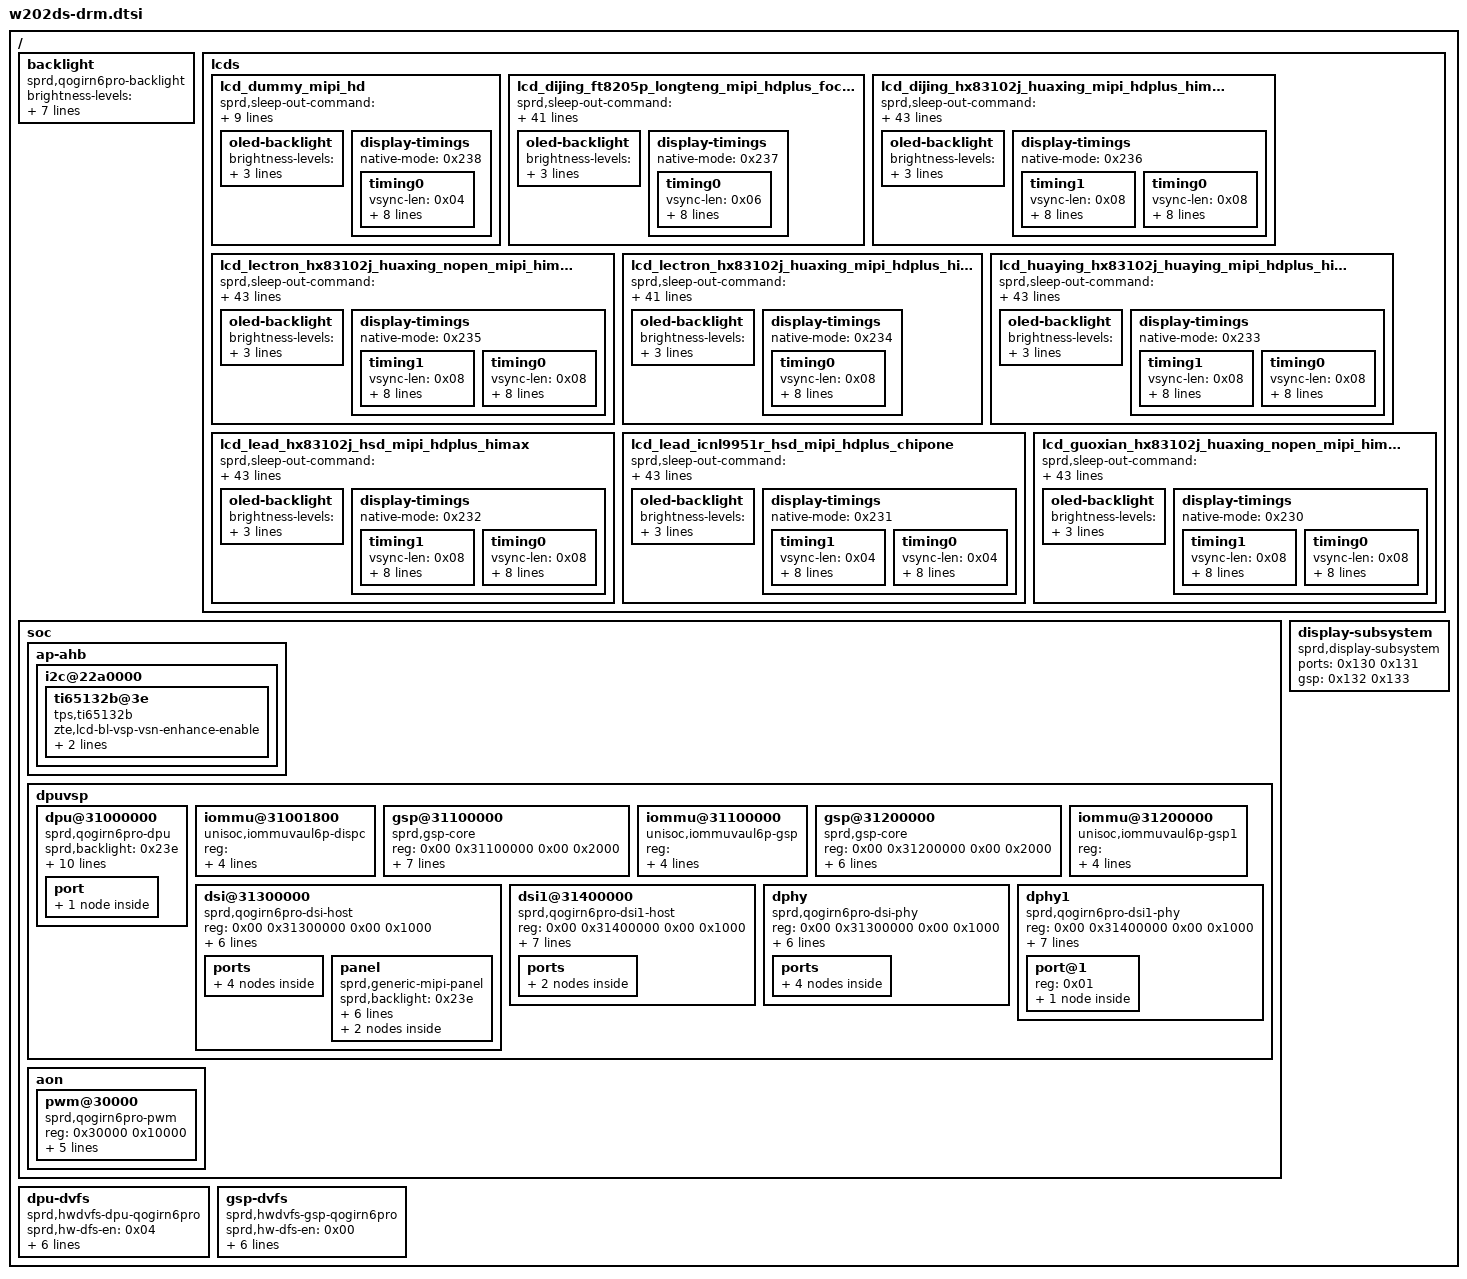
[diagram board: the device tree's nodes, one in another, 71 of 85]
// W202DS Server hardware layout; split from the validated imported tree.
/ {
	backlight {
		phandle = <0x23e>;
		brightness-levels = <0x00 0x0b 0x0b 0x0c 0x10 0x14 0x18 0x1c 0x20 0x24 0x28 0x2c 0x30 0x34 0x38 0x3c 0x40 0x44 0x48 0x4c 0x50 0x54 0x58 0x5c 0x60 0x64 0x68 0x6c 0x70 0x74 0x78 0x7c 0x80 0x84 0x88 0x8c 0x90 0x94 0x98 0x9c 0xa0 0xa4 0xa8 0xac 0xb0 0xb4 0xb8 0xbc 0xc0 0xc4 0xc8 0xcc 0xd0 0xd4 0xd8 0xdc 0xe0 0xe4 0xe8 0xec 0xf0 0xf4 0xf8 0xfc 0x100 0x104 0x108 0x10c 0x110 0x114 0x118 0x11c 0x120 0x124 0x128 0x12c 0x130 0x134 0x138 0x13c 0x140 0x144 0x148 0x14c 0x150 0x155 0x159 0x15d 0x161 0x165 0x169 0x16d 0x171 0x175 0x179 0x17d 0x181 0x185 0x189 0x18d 0x191 0x195 0x199 0x19d 0x1a1 0x1a5 0x1a9 0x1ad 0x1b1 0x1b5 0x1b9 0x1bd 0x1c1 0x1c5 0x1c9 0x1cd 0x1d1 0x1d5 0x1d9 0x1dd 0x1e1 0x1e5 0x1e9 0x1ed 0x1f1 0x1f5 0x1f9 0x1fd 0x201 0x205 0x209 0x20d 0x211 0x215 0x219 0x21d 0x221 0x225 0x229 0x22d 0x231 0x235 0x239 0x23d 0x241 0x245 0x249 0x24d 0x251 0x255 0x259 0x25d 0x261 0x265 0x269 0x26d 0x271 0x275 0x279 0x27d 0x281 0x285 0x289 0x28d 0x291 0x295 0x299 0x29d 0x2a1 0x2a5 0x2aa 0x2ae 0x2b2 0x2b6 0x2ba 0x2be 0x2c2 0x2c6 0x2ca 0x2ce 0x2d2 0x2d6 0x2da 0x2de 0x2e2 0x2e6 0x2ea 0x2ee 0x2f2 0x2f6 0x2fa 0x2fe 0x302 0x306 0x30a 0x30e 0x312 0x316 0x31a 0x31e 0x322 0x326 0x32a 0x32e 0x332 0x336 0x33a 0x33e 0x342 0x346 0x34a 0x34e 0x352 0x356 0x35a 0x35e 0x362 0x366 0x36a 0x36e 0x372 0x376 0x37a 0x37e 0x382 0x386 0x38a 0x38e 0x392 0x396 0x39a 0x39e 0x3a2 0x3a6 0x3aa 0x3ae 0x3b2 0x3b6 0x3ba 0x3be 0x3c2 0x3c6 0x3ca 0x3ce 0x3d2 0x3d6 0x3da 0x3de 0x3e2 0x3e6 0x3ea 0x3ee 0x3f2 0x3f6 0x3fa 0x3ff>;
		sprd,brightness-scale = <0x3ff>;
		default-brightness-level = <0x118>;
		sprd,min-brightness-level = <0x0b>;
		sprd,max-brightness-level = <0x3ff>;
		pwm-names = "backlight";
		pwms = <0x17a 0x00 0x9c40>;
		compatible = "sprd,qogirn6pro-backlight";
	};
	lcds {
		lcd_dummy_mipi_hd {
			phandle = <0x257>;
			sprd,sleep-out-command = [13 78 00 01 11 13 64 00 01 29];
			sprd,sleep-in-command = [13 0a 00 01 28 13 78 00 01 10];
			sprd,initial-command = [13 78 00 01 11 13 64 00 01 29];
			sprd,dsi-color-format = "rgb888";
			sprd,dsi-lane-number = <0x04>;
			sprd,dsi-work-mode = <0x01>;
			zte,panel-name = "lcd_dummy_mipi_hd_zte_cabc";
			oled-backlight {
				brightness-levels = [39 00 00 03 51 00 00 39 00 00 02 53 2c];
				sprd,max-level = <0xff>;
				default-brightness-level = <0x66>;
			};
			display-timings {
				native-mode = <0x238>;
				timing0 {
					phandle = <0x238>;
					vsync-len = <0x04>;
					hsync-len = <0x3c>;
					vfront-porch = <0x26>;
					vback-porch = <0x0c>;
					hfront-porch = <0x50>;
					hback-porch = <0x3c>;
					vactive = <0x500>;
					hactive = <0x2d0>;
					clock-frequency = <0x493e000>;
				};
			};
		};
		lcd_dijing_ft8205p_longteng_mipi_hdplus_focal {
			phandle = <0x256>;
			sprd,sleep-out-command = [05 78 00 01 11 05 14 00 01 29];
			sprd,sleep-in-command = <0x15010002 0xac0a3914 0x32800 0x397800 0x3100000>;
			sprd,initial-command = <0x29000002 0x415a2900 0x3415a 0x8290000 0x5808200 0x82002900 0x3415a 0x9290000 0x11801a01 0xab93a597 0x592ab106 0x80bf 0x85102900 0x119042 0x448414c6 0x239a11c0 0x23f4d507 0x20270029 0x11a0 0x809020aa 0x45555 0x5001e15 0x4200feff 0x29000011 0xb0037ef3 0x370137 0x1000000 0x4125004a 0x290000 0x11c00000 0x00 0x1204 0x2000700 0x8182900 0x3d000 0x290000 0x3415a0a 0x29000011 0x809191d4 0x14403342 0x4d576774 0x75818195 0x6f290000 0x11905f62 0x584f4332 0x27200c0b 0xa0e4033 0x424d2900 0x11a057 0x67747581 0x81956f5f 0x62584f43 0x32272029 0x4b0 0xc0b0a29 0x341 0x5a0b2900 0x118000 0x50b5c5 0xac0000a0 0x6a8ba9ae 0x22020029 0x1190 0xefd8b8f7 0x2570e008 0x11024013 0x4f4d3c35 0x29000009 0xa0f1a406 0xffff0003 0x290000 0x3415a0c 0x29000011 0x80fe6858 0x2bc3731 0x8000056 0x1005561 0x15290000 0x11905551 0x15560100 0x56010055 0x61155551 0x15562900 0x11a0b1 0x84010000 0x00 0x40940200 0x3029 0x11b0 0x28158004 0x180000 0x300a00 0x00 0x29000008 0xc0000105 0xc2b00000 0x29000003 0x415a0d29 0x1180 0x8000028 0x2000412 0x80277 0x24a10f0 0x29000007 0x90000258 0x1604a129 0x341 0x5a0e2900 0x1180ff 0x8168ec26 0xfd220055 0x55555505 0x5a5a8029 0x790 0x1000060 0x1002900 0x3415a 0xf290000 0x11801339 0xc1236304 0x80040602 0x28840b00 0x70032900 0x119019 0x4200006 0x1000a005 0x5a100000 0x90949229 0x11a0 0x1ddc41b3 0x65c04a0b 0x5a712280 0x194a0020 0x29000011 0xb0279e01 0xc0197a21 0x14004030 0xe0002dd0 0x82290000 0x11c00000 0x601863d0 0xa00d9a21 0x2106284 0x28032900 0x11d08a 0x88884892 0x90f151e 0xe0310604 0x2140429 0x11e0 0x102222bd 0x84c84124 0x10512d3e 0x64404000 0x29000010 0xf000de1a 0x4f5ffff 0x3f000015 0x40140000 0x29000003 0x415a1029 0x1180 0x3e7 0x8f0b003c 0x80016a0c 0x18c420c5 0x29000011 0x901c94d4 0x62cd3df8 0x33ff003 0x3f00ffff 0xff290000 0x3a08100 0x29000003 0x415a1129 0x880 0x00 0x29 0x341 0x5a122900 0x118000 0x00 0x00 0x00 0x129 0x1190 0x1100000 0x3c3cfbfb 0x00 0x00 0x29000011 0xa0000001 0x3c 0x3cfbfb14 0x3c3cfbfb 0x7290000 0x8b00100 0x00 0x82290000 0x3415a13 0x29000011 0x80000880 0x15009010 0x183e1000 0xd6030418 0x290000 0x11907088 0x30903270 0x3e978b39 0x30c409c4 0x9c42900 0x11a089 0x4fb643e0 0x9c409c4 0x9e00100 0x29 0x11b0 0x00 0xdb01 0x3175b942 0x86ca3175 0x29000011 0xc0b94286 0xca000000 0xc6000 0x24180009 0x6290000 0x11d04082 0x1906000 0x24d00109 0x7440021d 0x90402900 0x11e007 0x24d00109 0x1e461e46 0x20c5 0xf00c029 0xdf0 0x1040264e 0x4602c820 0x800c0000 0x29000003 0x415a1429 0x1180 0x102402c 0x99dfeff7 0x235f0300 0xc08398 0x29000011 0x9040be1a 0xb011c857 0x234c0ef 0x478026f8 0xfd290000 0x11a008d0 0xcbf1f01 0x9ae1f723 0x800700 0x2900 0x11b000 0x00 0x00 0x80 0x87078729 0x11c0 0x7050030 0x180ccf01 0xf29504c5 0xf40c20 0x29000011 0xd05f4950 0xc404f00 0xf29504c5 0xf41420 0x5f290000 0x11e04950 0xc404f02 0xf29504c5 0xf43420 0x5f492900 0x11f050 0xc404f04 0xf29504c5 0xf45420 0x5f495029 0x341 0x5a152900 0x11800c 0x404180df 0xf000000 0x00 0x29 0x1190 0x00 0x00 0x40ca03 0xe1e0f00 0x29000011 0xa000001c 0x08 0x42600e00 0x00 0x290000 0x11b00000 0x00 0x00 0x00 0x2900 0x11c000 0x00 0x00 0x601b00d8 0x150a629 0x11d0 0xc9341d47 0x510c4310 0x3cafeba2 0xa86ddbb6 0x29000011 0xe06ddbb6 0x6ddbb66d 0xdbb66ddb 0xb66ddbb6 0x6d290000 0x11f0dbb6 0x6d25c934 0x19064108 0x2003caf 0xeb202900 0x3415a 0x16290000 0x1180a86d 0xdbb66ddb 0xb66ddbb6 0x6ddbb66d 0xdbb62900 0x11906d 0xdbb66ddb 0xb66d490a 0xa0a0a00 0x29 0x11a0 0x00 0x00 0x00 0xc01fe101 0x29000011 0xb0280200 0x00 0x04 0x00 0x290000 0x11c00000 0x00 0x2060000 0x00 0x2002900 0x11d000 0x00 0x04 0x00 0x29 0x11e0 0x00 0x1000000 0x00 0x00 0x29000011 0xf0000400 0x00 0x00 0x20000000 0x290000 0x3415a17 0x29000011 0x80000000 0x400 0x00 0x00 0x20290000 0x11900000 0x00 0x10 0x00 0x2900 0x11a000 0x00 0x1000 0x00 0x29 0x11b0 0x40000000 0x00 0x100 0x00 0x29000011 0xc0000000 0x100000 0x00 0x00 0x290000 0x7d00001 0x00 0x29000003 0x415a1829 0x1180 0x7f7ffefe 0xfefefefe 0xfefefefe 0xd47fd4d4 0x29000011 0x90d4d4d4 0xd4d4d4d4 0xd4aaaaaa 0xaaaaaaaa 0xaa290000 0x11a0aaaa 0xaaaa7f7f 0x7f7f7f7f 0x7f7f7f7f 0x7f7f2900 0x11b07c 0x83798679 0x86798679 0x8679867a 0x837a8529 0x11c0 0x7a857a85 0x7a857a85 0x7b847b84 0x7b847b84 0x29000011 0xd07b847b 0x847c837c 0x837c837c 0x837c837c 0x83290000 0x11e0fe7f 0x7ffefefe 0xfefefefe 0xfefefed4 0x7fd42900 0x11f0d4 0xd4d4d4d4 0xd4d4d4d4 0xaaaaaaaa 0xaaaaaa29 0x341 0x5a192900 0x1180aa 0xaaaaaaaa 0x7f7f7f7f 0x7f7f7f7f 0x7f7f7f29 0x1190 0x7f7c8379 0x86798679 0x86798679 0x867a837a 0x29000011 0xa0857a85 0x7a857a85 0x7a857b84 0x7b847b84 0x7b290000 0x11b0847b 0x847b847c 0x837c837c 0x837c837c 0x837c2900 0x11c083 0x7f04ff1e 0x81018 0x20283038 0xfc000429 0xcd0 0x20000108 0x40000210 0x8000fc29 0x341 0x5a1a2900 0x1180f0 0xd9c8baaf 0xa69e9892 0x8d888400 0x60f6cf29 0x1190 0xfc6ff6ef 0xcfaf5f55 0xf800f8 0xf8ad8d 0x29000011 0xa0736053 0x4a437f78 0x10a03f00 0x00 0x290000 0x11b00000 0x00 0x00 0x00 0x2900 0x9c000 0x00 0x29 0x341 0x5a1c2900 0x118000 0x4080c00 0x1014181c 0x202830 0x38004029 0x1190 0x48505800 0x60687078 0x808890 0x9800a0a8 0x29000011 0xa0b0b800 0xc0c8d0d8 0xe0e8f0 0xf800fcfe 0xff290000 0x11b00000 0x4080c00 0x1014181c 0x202830 0x38002900 0x11c040 0x48505800 0x60687078 0x808890 0x9800a029 0x11d0 0xa8b0b800 0xc0c8d0d8 0xe0e8f0 0xf800fcfe 0x29000011 0xe0ff0000 0x4080c00 0x1014181c 0x202830 0x38290000 0x11f00040 0x48505800 0x60687078 0x808890 0x98002900 0x3415a 0x1d290000 0x1180a0a8 0xb0b800c0 0xc8d0d800 0xe0e8f0f8 0xfc2900 0x590fe 0xff000029 0x341 0x5a1f2900 0x11805a 0xf700928 0x30384048 0x50586020 0x30384029 0x1190 0x48505860 0x20283840 0x48505860 0x20283040 0x29000011 0xa0485058 0x60202830 0x38485058 0x60202830 0x38290000 0x11b04050 0x58602028 0x30384048 0x58602028 0x30382900 0x11c040 0x48506020 0x28303840 0x485058ff 0x5a1e2029 0xdd0 0x22000 0x2200002 0x200002fe 0x29000003 0x415a2029 0x1180 0x44730300 0xcaf3ff6b 0x10080208 0x3411830 0x29000011 0x901844e1 0x40e12030 0x18c82141 0x1391344 0x42290000 0x11a09150 0x28140a85 0x3d2b080 0x367fd01f 0x12e02900 0x11b018 0x361b1104 0x2002d080 0xb3213820 0x18880329 0x11c0 0x82014d70 0x40308d0d 0xa4a20080 0x4380050 0x29000011 0xd08013e0 0x14c070 0x4000e081 0x280e 0x6290000 0x11e04355 0x55555555 0xd5cccccc 0xcccc4c08 0x82c62900 0x11f0e0 0x1000000 0x21428800 0x00 0x2029 0x341 0x5a212900 0x118004 0x41064990 0x4490000 0x49000049 0x4929 0x1190 0x90040085 0x110c0000 0x40000000 0x1600a5 0x29000011 0xa0000808 0x1510d1b6 0x45928a20 0xa26d0b00 0x54290000 0x11b04044 0xdb160048 0x922409e0 0xf805530 0x1102900 0x11c001 0x42821120 0x2101001 0x8880004 0x44000229 0x11d0 0x22000491 0x801f0040 0x40040000 0x181016 0x29000003 0xe0100029 0x341 0x5a222900 0x118029 0xd3005555 0x55555555 0x55555555 0x551f7029 0x490 0xf0000029 0x341 0x5a232900 0x118009 0x1020500 0x5040000 0x00 0x29 0xa90 0xff1f20 0x10000 0xfe290000 0x3415a24 0x29000011 0x80000300 0xffff6600 0x00 0x95 0x57290000 0xf905aa5 0x5a000000 0x22223a 0x22000000 0x29000003 0x415a2429 0x290 0xa5290000 0x3415a13 0x29000002 0xb6db2900 0x3415a 0x2f290000 0x24c0329 0x209 0x290000 0x3510000 0x29000002 0x35002900 0x25324 0x29000002 0x55000578 0x11105 0xa000129>;
			sprd,use-gen-write;
			sprd,reset-off-sequence = <0x01 0x14>;
			sprd,reset-on-sequence = <0x01 0x05 0x00 0x02 0x01 0x37>;
			sprd,dphy-taget-val = <0x05>;
			sprd,esd-check-value = <0x9c>;
			sprd,esd-check-register = <0x0a>;
			sprd,esd-check-period = <0x7d0>;
			sprd,esd-check-mode = <0x01>;
			sprd,esd-check-enable = <0x00>;
			sprd,height-mm = <0x39960>;
			sprd,width-mm = <0x23fdc>;
			sprd,phy-escape-clock = <0x4e20>;
			sprd,phy-bit-clock = <0x10cc50>;
			sprd,dual-dsi-enable = <0x00>;
			sprd,dsc-enable = <0x00>;
			sprd,output-bpc = <0x08>;
			sprd,slice-height = <0x14>;
			sprd,slice-width = <0x258>;
			sprd,hporch-lp-disable = <0x01>;
			sprd,video-lp-cmd-enable = <0x01>;
			sprd,dpi-clk-div = <0x06>;
			sprd,dsi-color-format = "rgb888";
			sprd,dsi-lane-number = <0x04>;
			sprd,dsi-work-mode = <0x01>;
			zte,lcd-disable-mipi-hop;
			zte,lcd-version-v000;
			zte,lcd-delay-open-bl-value = <0x64>;
			zte,panel-name = "lcd_dijing_ft8205p_longteng_mipi_hdplus_focal";
			zte,lcd-disable-ssc;
			zte,lcd_bl_vsp_vsn_voltage = <0x14>;
			zte,lcm_backlight_curve_mode = "lcd_brightness_max_450_lux";
			zte,lcd-backlight-register-bit-length = <0x0c>;
			zte,lcd-init-code-version = "20240826";
			oled-backlight {
				brightness-levels = [39 00 00 03 51 00 00 39 00 00 02 53 2c];
				sprd,max-level = <0xfff>;
				default-brightness-level = <0x666>;
			};
			display-timings {
				native-mode = <0x237>;
				timing0 {
					phandle = <0x237>;
					vsync-len = <0x06>;
					hsync-len = <0x0a>;
					vfront-porch = <0xe0>;
					vback-porch = <0x20>;
					hfront-porch = <0x56>;
					hback-porch = <0x68>;
					vactive = <0x780>;
					hactive = <0x4b0>;
					clock-frequency = <0xaefaec0>;
				};
			};
		};
		lcd_dijing_hx83102j_huaxing_mipi_hdplus_himax {
			phandle = <0x254>;
			sprd,sleep-out-command = [05 78 00 01 11 05 14 00 01 29];
			sprd,sleep-in-command = <0x15010002 0xac0a3914 0x32800 0x397800 0x3100000>;
			zte,initial-command-fps90 = [39 00 00 06 b9 83 10 21 55 00 15 00 00 02 e9 c4 15 00 00 02 d9 d1 15 00 00 02 e9 3f 39 00 00 12 b1 2c b5 b5 31 f1 33 dc 52 3a 3a 3a 3a 32 8b 11 e5 98 15 00 00 02 e9 d9 39 00 00 03 b1 8b 33 15 00 00 02 e9 3f 39 00 00 10 b2 00 47 b0 80 01 2c b0 3c 4c 12 30 00 00 98 51 39 00 00 12 b4 48 48 48 48 48 48 4a 4c 2a 4c 01 6b 01 02 01 00 00 39 00 00 03 bc 1b 04 15 00 00 02 be 20 39 00 00 09 bf fc c4 80 9c 36 00 0d 04 39 00 00 0b c0 32 32 22 11 22 a0 31 08 f5 03 15 00 00 02 e9 cc 15 00 00 02 c7 80 15 00 00 02 e9 3f 15 00 00 02 e9 c6 15 00 00 02 c8 97 15 00 00 02 e9 3f 39 00 00 06 c9 00 1e 13 88 01 39 00 00 07 cb 08 13 07 00 08 ae 39 00 00 04 cc 02 03 4c 39 00 00 08 d1 07 06 00 02 04 2c ff 39 00 00 23 d3 06 00 00 00 40 04 08 04 08 37 07 44 37 2b 2b 03 03 32 10 22 00 0b 32 10 29 00 29 32 10 08 00 08 00 00 39 00 00 2d d5 18 18 18 18 18 18 18 18 18 18 07 06 07 06 05 04 05 04 03 02 03 02 01 00 01 00 18 18 25 24 25 24 1f 1f 1f 1f 1e 1e 1e 1e 20 20 20 20 39 00 00 0d d8 0a 2a aa 8a aa a0 0a 2a aa 8a aa a0 39 00 00 2d e1 11 00 00 89 30 80 07 80 02 58 00 14 02 58 02 58 02 00 02 2c 00 20 02 02 00 08 00 0c 05 0e 04 94 18 00 10 f0 03 0c 20 00 06 0b 0b 33 39 00 00 1c e7 12 10 10 3f 1e 9d 02 52 9d 14 14 00 00 00 00 96 0a 01 02 00 33 02 04 18 01 69 77 15 00 00 02 bd 01 39 00 00 05 b1 01 7f 11 fd 15 00 00 02 e9 c5 15 00 00 02 ba 4f 15 00 00 02 e9 3f 15 00 00 02 cb 86 15 00 00 02 d2 64 15 00 00 02 e9 c5 15 00 00 02 d3 00 15 00 00 02 e9 3f 39 00 00 19 d8 0a 2a aa 8a aa a0 0a 2a aa 8a aa a0 05 15 55 45 55 50 05 15 55 45 55 50 15 00 00 02 e9 d1 39 00 00 0a e1 f6 2b 34 2b 74 3b 74 6b f4 15 00 00 02 e9 3f 39 00 00 0c e7 01 00 24 01 7e 0f 7c 10 a0 00 00 15 00 00 02 bd 02 39 00 00 06 cb 03 07 00 09 67 39 00 00 0d d8 0f 3f ff cf ff f0 0f 3f ff cf ff f0 39 00 00 1d e7 fe 01 fe 01 fe 01 00 00 00 23 00 23 81 02 40 00 20 6b 02 01 00 00 00 00 00 00 01 00 15 00 00 02 bd 03 39 00 00 03 b2 66 81 15 00 00 02 e9 c6 39 00 00 04 b4 03 ff f8 15 00 00 02 e9 3f 39 00 00 25 d8 0a 2a aa 8a aa a0 0a 2a aa 8a aa a0 0f 2a aa 8a aa f0 0f 2a aa 8a aa f0 0a 2a aa 8a aa a0 0a 2a aa 8a aa a0 15 00 00 02 e1 01 15 00 00 02 bd 00 39 00 00 05 b9 00 00 00 00 39 00 00 03 51 00 00 39 00 00 02 35 00 39 00 00 02 53 24 39 00 00 02 55 00 05 64 00 01 11 05 14 00 01 29];
			sprd,initial-command = <0x39000006 0xb9831021 0x55001500 0x2e9c4 0x15000002 0xd9d11500 0x2e93f 0x39000012 0xb12cb5b5 0x31f133dc 0x523a3a3a 0x3a328b11 0xe5981500 0x2e9d9 0x39000003 0xb18b3315 0x2e9 0x3f390000 0x10b20047 0xb080012c 0xb03c4c12 0x30000098 0x51390000 0x12b44848 0x48484848 0x4a4c2a4c 0x16b0102 0x1000039 0x3bc 0x1b041500 0x2be20 0x39000009 0xbffcc480 0x9c36000d 0x4390000 0xbc03232 0x221122a0 0x3108f503 0x15000002 0xe9cc1500 0x2c780 0x15000002 0xe93f1500 0x2e9c6 0x15000002 0xc8971500 0x2e93f 0x39000006 0xc9001e13 0x88013900 0x7cb08 0x13070008 0xae390000 0x4cc0203 0x4c390000 0x8d10706 0x2042c 0xff390000 0x23d30600 0x4004 0x8040837 0x744372b 0x2b030332 0x1022000b 0x32102900 0x29321008 0x80000 0x3900002d 0xd5181818 0x18181818 0x18181807 0x6070605 0x4050403 0x2030201 0x10018 0x18252425 0x241f1f1f 0x1f1e1e1e 0x1e202020 0x20390000 0xdd80a2a 0xaa8aaaa0 0xa2aaa8a 0xaaa03900 0x2de111 0x8930 0x80078002 0x58001402 0x58025802 0x22c00 0x20020200 0x8000c05 0xe049418 0x10f003 0xc200006 0xb0b3339 0x1ce7 0x1210103f 0x1e9d0252 0x9d141400 0x96 0xa010200 0x33020418 0x1697739 0x2fe0 0xa1821 0x2a4b6469 0x6f688082 0x85918d93 0x9aabaa53 0x5b667300 0xb18212a 0x4b64696f 0x68808285 0x918d939a 0xacaa535b 0x67731500 0x2bd01 0x39000005 0xb1017f11 0xfd150000 0x2e9c515 0x2ba 0x4f150000 0x2e93f15 0x2cb 0x86150000 0x2d26415 0x2e9 0xc5150000 0x2d30015 0x2e9 0x3f390000 0x19d80a2a 0xaa8aaaa0 0xa2aaa8a 0xaaa00515 0x55455550 0x5155545 0x55501500 0x2e9d1 0x3900000a 0xe1f62b34 0x2b743b74 0x6bf41500 0x2e93f 0x3900000c 0xe7010024 0x17e0f7c 0x10a00000 0x15000002 0xbd023900 0x6cb03 0x7000967 0x3900000d 0xd80f3fff 0xcffff00f 0x3fffcfff 0xf0390000 0x1de7fe01 0xfe01fe01 0x23 0x238102 0x4000206b 0x2010000 0x00 0x1001500 0x2bd03 0x39000003 0xb2668115 0x2e9 0xc6390000 0x4b403ff 0xf8150000 0x2e93f39 0x25d8 0xa2aaa8a 0xaaa00a2a 0xaa8aaaa0 0xf2aaa8a 0xaaf00f2a 0xaa8aaaf0 0xa2aaa8a 0xaaa00a2a 0xaa8aaaa0 0x15000002 0xe1011500 0x2bd00 0x39000005 0xb9000000 0x390000 0x3510000 0x39000002 0x35003900 0x25324 0x39000002 0x55000564 0x11105 0x14000129>;
			sprd,use-gen-write;
			sprd,reset-off-sequence = <0x01 0x14>;
			sprd,reset-on-sequence = <0x01 0x05 0x00 0x02 0x01 0x37>;
			sprd,dphy-taget-val = <0x05>;
			sprd,esd-check-value = <0x9c>;
			sprd,esd-check-register = <0x0a>;
			sprd,esd-check-period = <0x7d0>;
			sprd,esd-check-mode = <0x01>;
			sprd,esd-check-enable = <0x01>;
			sprd,height-mm = <0x39960>;
			sprd,width-mm = <0x23fdc>;
			sprd,phy-escape-clock = <0x4e20>;
			sprd,phy-bit-clock = <0xdac00>;
			sprd,dual-dsi-enable = <0x00>;
			sprd,dsc-enable = <0x01>;
			sprd,output-bpc = <0x08>;
			sprd,slice-height = <0x14>;
			sprd,slice-width = <0x258>;
			sprd,hporch-lp-disable = <0x00>;
			sprd,video-lp-cmd-enable = <0x00>;
			sprd,dpi-clk-div = <0x00>;
			sprd,dsi-color-format = "dsc";
			sprd,dsi-lane-number = <0x04>;
			sprd,dsi-work-mode = <0x01>;
			zte,lcd-disable-mipi-hop;
			zte,lcd-version-v000;
			zte,lcd-delay-open-bl-value = <0x64>;
			zte,panel-name = "lcd_dijing_hx83102j_huaxing_mipi_hdplus_himax";
			zte,lcd-disable-ssc;
			zte,lcd_bl_vsp_vsn_voltage = <0x14>;
			zte,lcm_backlight_curve_mode = "lcd_brightness_max_450_lux";
			zte,lcd-backlight-register-bit-length = <0x0c>;
			zte,lcd-init-code-version = "20250110";
			oled-backlight {
				brightness-levels = [39 00 00 03 51 00 00 39 00 00 02 53 2c];
				sprd,max-level = <0xfff>;
				default-brightness-level = <0x666>;
			};
			display-timings {
				native-mode = <0x236>;
				timing1 {
					phandle = <0x255>;
					vsync-len = <0x08>;
					hsync-len = <0x04>;
					vfront-porch = <0x120>;
					vback-porch = <0x1c>;
					hfront-porch = <0x9c>;
					hback-porch = <0xa0>;
					vactive = <0x780>;
					hactive = <0x4b0>;
					clock-frequency = <0x124f8000>;
				};
				timing0 {
					phandle = <0x236>;
					vsync-len = <0x08>;
					hsync-len = <0x04>;
					vfront-porch = <0x580>;
					vback-porch = <0x1c>;
					hfront-porch = <0x9c>;
					hback-porch = <0xa0>;
					vactive = <0x780>;
					hactive = <0x4b0>;
					clock-frequency = <0x124f8000>;
				};
			};
		};
		lcd_lectron_hx83102j_huaxing_nopen_mipi_himax {
			phandle = <0x252>;
			sprd,sleep-out-command = [05 78 00 01 11 05 14 00 01 29];
			sprd,sleep-in-command = <0x15010002 0xac0a3914 0x32800 0x397800 0x3100000>;
			zte,initial-command-fps90 = [39 00 00 06 b9 83 10 21 55 00 15 00 00 02 e9 c4 15 00 00 02 d9 d1 15 00 00 02 e9 3f 39 00 00 12 b1 2c b5 b5 31 f1 33 dc 52 3a 3a 3a 3a 32 8b 11 e5 98 15 00 00 02 e9 d9 39 00 00 03 b1 8b 33 15 00 00 02 e9 3f 39 00 00 10 b2 00 47 b0 80 01 2c b0 3c 4c 12 30 00 00 98 51 39 00 00 12 b4 48 48 48 48 48 48 4a 4c 2a 4c 01 6b 01 02 01 00 00 39 00 00 03 bc 1b 04 15 00 00 02 be 20 39 00 00 09 bf fc c4 80 9c 36 00 0d 04 39 00 00 0b c0 32 32 22 11 22 a0 31 08 f5 03 15 00 00 02 e9 cc 15 00 00 02 c7 80 15 00 00 02 e9 3f 15 00 00 02 e9 c6 15 00 00 02 c8 97 15 00 00 02 e9 3f 39 00 00 06 c9 00 1e 13 88 01 39 00 00 07 cb 08 13 07 00 08 ae 39 00 00 04 cc 02 03 4c 39 00 00 08 d1 07 06 00 02 04 2c ff 39 00 00 23 d3 06 00 00 00 40 04 08 04 08 37 07 44 37 2b 2b 03 03 32 10 22 00 0b 32 10 29 00 29 32 10 08 00 08 00 00 39 00 00 2d d5 18 18 18 18 18 18 18 18 18 18 07 06 07 06 05 04 05 04 03 02 03 02 01 00 01 00 18 18 25 24 25 24 1f 1f 1f 1f 1e 1e 1e 1e 20 20 20 20 39 00 00 0d d8 0a 2a aa 8a aa a0 0a 2a aa 8a aa a0 39 00 00 2d e1 11 00 00 89 30 80 07 80 02 58 00 14 02 58 02 58 02 00 02 2c 00 20 02 02 00 08 00 0c 05 0e 04 94 18 00 10 f0 03 0c 20 00 06 0b 0b 33 39 00 00 1c e7 12 10 10 3f 1e 9d 02 52 9d 14 14 00 00 00 00 96 0a 01 02 00 33 02 04 18 01 69 77 15 00 00 02 bd 01 39 00 00 05 b1 01 7f 11 fd 15 00 00 02 e9 c5 15 00 00 02 ba 4f 15 00 00 02 e9 3f 15 00 00 02 cb 86 15 00 00 02 d2 64 15 00 00 02 e9 c5 15 00 00 02 d3 00 15 00 00 02 e9 3f 39 00 00 19 d8 0a 2a aa 8a aa a0 0a 2a aa 8a aa a0 05 15 55 45 55 50 05 15 55 45 55 50 15 00 00 02 e9 d1 39 00 00 0a e1 f6 2b 34 2b 74 3b 74 6b f4 15 00 00 02 e9 3f 39 00 00 0c e7 01 00 24 01 7e 0f 7c 10 a0 00 00 15 00 00 02 bd 02 39 00 00 06 cb 03 07 00 09 67 39 00 00 0d d8 0f 3f ff cf ff f0 0f 3f ff cf ff f0 39 00 00 1d e7 fe 01 fe 01 fe 01 00 00 00 23 00 23 81 02 40 00 20 6b 02 01 00 00 00 00 00 00 01 00 15 00 00 02 bd 03 39 00 00 03 b2 66 81 15 00 00 02 e9 c6 39 00 00 04 b4 03 ff f8 15 00 00 02 e9 3f 39 00 00 25 d8 0a 2a aa 8a aa a0 0a 2a aa 8a aa a0 0f 2a aa 8a aa f0 0f 2a aa 8a aa f0 0a 2a aa 8a aa a0 0a 2a aa 8a aa a0 15 00 00 02 e1 01 15 00 00 02 bd 00 39 00 00 05 b9 00 00 00 00 39 00 00 03 51 00 00 39 00 00 02 35 00 39 00 00 02 53 24 39 00 00 02 55 00 05 64 00 01 11 05 14 00 01 29];
			sprd,initial-command = <0x39000006 0xb9831021 0x55001500 0x2e9c4 0x15000002 0xd9d11500 0x2e93f 0x39000012 0xb12cb5b5 0x31f133dc 0x523a3a3a 0x3a328b11 0xe5981500 0x2e9d9 0x39000003 0xb18b3315 0x2e9 0x3f390000 0x10b20047 0xb080012c 0xb03c4c12 0x30000098 0x51390000 0x12b44848 0x48484848 0x4a4c2a4c 0x16b0102 0x1000039 0x3bc 0x1b041500 0x2be20 0x39000009 0xbffcc480 0x9c36000d 0x4390000 0xbc03232 0x221122a0 0x3108f503 0x15000002 0xe9cc1500 0x2c780 0x15000002 0xe93f1500 0x2e9c6 0x15000002 0xc8971500 0x2e93f 0x39000006 0xc9001e13 0x88013900 0x7cb08 0x13070008 0xae390000 0x4cc0203 0x4c390000 0x8d10706 0x2042c 0xff390000 0x23d30600 0x4004 0x8040837 0x744372b 0x2b030332 0x1022000b 0x32102900 0x29321008 0x80000 0x3900002d 0xd5181818 0x18181818 0x18181807 0x6070605 0x4050403 0x2030201 0x10018 0x18252425 0x241f1f1f 0x1f1e1e1e 0x1e202020 0x20390000 0xdd80a2a 0xaa8aaaa0 0xa2aaa8a 0xaaa03900 0x2de111 0x8930 0x80078002 0x58001402 0x58025802 0x22c00 0x20020200 0x8000c05 0xe049418 0x10f003 0xc200006 0xb0b3339 0x1ce7 0x1210103f 0x1e9d0252 0x9d141400 0x96 0xa010200 0x33020418 0x1697739 0x2fe0 0xa1821 0x2a4b6469 0x6f688082 0x85918d93 0x9aabaa53 0x5b667300 0xb18212a 0x4b64696f 0x68808285 0x918d939a 0xacaa535b 0x67731500 0x2bd01 0x39000005 0xb1017f11 0xfd150000 0x2e9c515 0x2ba 0x4f150000 0x2e93f15 0x2cb 0x86150000 0x2d26415 0x2e9 0xc5150000 0x2d30015 0x2e9 0x3f390000 0x19d80a2a 0xaa8aaaa0 0xa2aaa8a 0xaaa00515 0x55455550 0x5155545 0x55501500 0x2e9d1 0x3900000a 0xe1f62b34 0x2b743b74 0x6bf41500 0x2e93f 0x3900000c 0xe7010024 0x17e0f7c 0x10a00000 0x15000002 0xbd023900 0x6cb03 0x7000967 0x3900000d 0xd80f3fff 0xcffff00f 0x3fffcfff 0xf0390000 0x1de7fe01 0xfe01fe01 0x23 0x238102 0x4000206b 0x2010000 0x00 0x1001500 0x2bd03 0x39000003 0xb2668115 0x2e9 0xc6390000 0x4b403ff 0xf8150000 0x2e93f39 0x25d8 0xa2aaa8a 0xaaa00a2a 0xaa8aaaa0 0xf2aaa8a 0xaaf00f2a 0xaa8aaaf0 0xa2aaa8a 0xaaa00a2a 0xaa8aaaa0 0x15000002 0xe1011500 0x2bd00 0x39000005 0xb9000000 0x390000 0x3510000 0x39000002 0x35003900 0x25324 0x39000002 0x55000564 0x11105 0x14000129>;
			sprd,use-gen-write;
			sprd,reset-off-sequence = <0x01 0x14>;
			sprd,reset-on-sequence = <0x01 0x05 0x00 0x02 0x01 0x37>;
			sprd,dphy-taget-val = <0x05>;
			sprd,esd-check-value = <0x9c>;
			sprd,esd-check-register = <0x0a>;
			sprd,esd-check-period = <0x7d0>;
			sprd,esd-check-mode = <0x01>;
			sprd,esd-check-enable = <0x01>;
			sprd,height-mm = <0x39960>;
			sprd,width-mm = <0x23fdc>;
			sprd,phy-escape-clock = <0x4e20>;
			sprd,phy-bit-clock = <0xdac00>;
			sprd,dual-dsi-enable = <0x00>;
			sprd,dsc-enable = <0x01>;
			sprd,output-bpc = <0x08>;
			sprd,slice-height = <0x14>;
			sprd,slice-width = <0x258>;
			sprd,hporch-lp-disable = <0x00>;
			sprd,video-lp-cmd-enable = <0x00>;
			sprd,dpi-clk-div = <0x00>;
			sprd,dsi-color-format = "dsc";
			sprd,dsi-lane-number = <0x04>;
			sprd,dsi-work-mode = <0x01>;
			zte,lcd-disable-mipi-hop;
			zte,lcd-version-v000;
			zte,lcd-delay-open-bl-value = <0x64>;
			zte,panel-name = "lcd_lectron_hx83102j_huaxing_nopen_mipi_himax";
			zte,lcd-disable-ssc;
			zte,lcd_bl_vsp_vsn_voltage = <0x14>;
			zte,lcm_backlight_curve_mode = "lcd_brightness_max_450_lux";
			zte,lcd-backlight-register-bit-length = <0x0c>;
			zte,lcd-init-code-version = "20241111";
			oled-backlight {
				brightness-levels = [39 00 00 03 51 00 00 39 00 00 02 53 2c];
				sprd,max-level = <0xfff>;
				default-brightness-level = <0x666>;
			};
			display-timings {
				native-mode = <0x235>;
				timing1 {
					phandle = <0x253>;
					vsync-len = <0x08>;
					hsync-len = <0x04>;
					vfront-porch = <0x120>;
					vback-porch = <0x1c>;
					hfront-porch = <0x9c>;
					hback-porch = <0xa0>;
					vactive = <0x780>;
					hactive = <0x4b0>;
					clock-frequency = <0x124f8000>;
				};
				timing0 {
					phandle = <0x235>;
					vsync-len = <0x08>;
					hsync-len = <0x04>;
					vfront-porch = <0x580>;
					vback-porch = <0x1c>;
					hfront-porch = <0x9c>;
					hback-porch = <0xa0>;
					vactive = <0x780>;
					hactive = <0x4b0>;
					clock-frequency = <0x124f8000>;
				};
			};
		};
		lcd_lectron_hx83102j_huaxing_mipi_hdplus_himax {
			phandle = <0x251>;
			sprd,sleep-out-command = [05 78 00 01 11 05 14 00 01 29];
			sprd,sleep-in-command = <0x15010002 0xac0a3914 0x32800 0x397800 0x3100000>;
			sprd,initial-command = <0x39000006 0xb9831021 0x55003900 0x2e9c4 0x39000002 0xd9d13900 0x2e93f 0x39000012 0xb12cb3b3 0x31f133e0 0x5436363a 0x3a328b11 0xe5983900 0x2e9d9 0x39000003 0xb18b3339 0x2e9 0x3f390000 0x10b20047 0xb080002c 0x803c9f22 0x20000098 0x51390000 0x12b46464 0x64646464 0x40846484 0x19d0102 0x1000039 0x3bc 0x1b043900 0x2be20 0x39000009 0xbffcc480 0x9c36000d 0x4390000 0xbc03232 0x221122a0 0x3108f503 0x39000002 0xe9cc3900 0x2c780 0x39000002 0xe93f3900 0x2e9c6 0x39000002 0xc8973900 0x2e93f 0x39000006 0xc9001e13 0x88013900 0x7cb08 0x1307000f 0x36390000 0x4cc0203 0x44390000 0x8d10706 0x2042c 0xff390000 0x23d30600 0x4004 0x8040837 0x744372b 0x2b030332 0x10220025 0x32102900 0x29321008 0x80000 0x3900002d 0xd5181818 0x18181818 0x18181807 0x6070605 0x4050403 0x2030201 0x10018 0x18252425 0x241f1f1f 0x1f1e1e1e 0x1e202020 0x20390000 0xdd80a2a 0xaa8aaaa0 0xa2aaa8a 0xaaa03900 0x2de111 0x8930 0x80078002 0x58001402 0x58025802 0x22c00 0x20020200 0x8000c05 0xe049418 0x10f003 0xc200006 0xb0b3339 0xce7 0xe010100d 0x1e9d0252 0x9d141439 0x2fe0 0xa1821 0x2a4b6469 0x6f688082 0x85918d93 0x9aabaa53 0x5b667300 0xb18212a 0x4b64696f 0x68808285 0x918d939a 0xacaa535b 0x67733900 0x2bd01 0x39000005 0xb1017f11 0xfd390000 0x2e9c539 0x2ba 0x4f390000 0x2e93f39 0x2e9 0xd1390000 0xae1f62b 0x342b743b 0x746bf439 0x2e9 0x3f390000 0x2cb8639 0x2d2 0x64390000 0x2e9c539 0x2d3 0x390000 0x2e93f39 0x19d8 0xa2aaa8a 0xaaa00a2a 0xaa8aaaa0 0x5155545 0x55500515 0x55455550 0x3900000c 0xe7020024 0x17e0f7c 0x10a00000 0x39000002 0xbd023900 0x6cb03 0x700107b 0x3900000d 0xd80f3fff 0xcffff00f 0x3fffcfff 0xf0390000 0x1de7fe01 0xfe01fe01 0x23 0x238102 0x4000209d 0x2010000 0x00 0x1003900 0x2bd03 0x39000003 0xb2668139 0x2e9 0xc6390000 0x4b403ff 0xf8390000 0x2e93f39 0x2e1 0x390000 0x25d80a2a 0xaa8aaaa0 0xa2aaa8a 0xaaa00f2a 0xaa8aaaf0 0xf2aaa8a 0xaaf00a2a 0xaa8aaaa0 0xa2aaa8a 0xaaa03900 0x2bd00 0x39000005 0xb9000000 0x390000 0x3510000 0x39000002 0x35003900 0x25324 0x39000002 0x55000564 0x11105 0x14000129>;
			sprd,use-gen-write;
			sprd,reset-off-sequence = <0x01 0x14>;
			sprd,reset-on-sequence = <0x01 0x05 0x00 0x02 0x01 0x37>;
			sprd,dphy-taget-val = <0x05>;
			sprd,esd-check-value = <0x9c>;
			sprd,esd-check-register = <0x0a>;
			sprd,esd-check-period = <0x7d0>;
			sprd,esd-check-mode = <0x01>;
			sprd,esd-check-enable = <0x01>;
			sprd,height-mm = <0x39960>;
			sprd,width-mm = <0x23fdc>;
			sprd,phy-escape-clock = <0x4e20>;
			sprd,phy-bit-clock = <0x10cc50>;
			sprd,dual-dsi-enable = <0x00>;
			sprd,dsc-enable = <0x00>;
			sprd,output-bpc = <0x08>;
			sprd,slice-height = <0x14>;
			sprd,slice-width = <0x258>;
			sprd,hporch-lp-disable = <0x01>;
			sprd,video-lp-cmd-enable = <0x01>;
			sprd,dpi-clk-div = <0x06>;
			sprd,dsi-color-format = "rgb888";
			sprd,dsi-lane-number = <0x04>;
			sprd,dsi-work-mode = <0x01>;
			zte,lcd-disable-mipi-hop;
			zte,lcd-version-v000;
			zte,lcd-delay-open-bl-value = <0x64>;
			zte,panel-name = "lcd_lectron_hx83102j_huaxing_mipi_hdplus_himax";
			zte,lcd-disable-ssc;
			zte,lcd_bl_vsp_vsn_voltage = <0x14>;
			zte,lcm_backlight_curve_mode = "lcd_brightness_max_450_lux";
			zte,lcd-backlight-register-bit-length = <0x0c>;
			zte,lcd-init-code-version = "20240621";
			oled-backlight {
				brightness-levels = [39 00 00 03 51 00 00 39 00 00 02 53 2c];
				sprd,max-level = <0xfff>;
				default-brightness-level = <0x666>;
			};
			display-timings {
				native-mode = <0x234>;
				timing0 {
					phandle = <0x234>;
					vsync-len = <0x08>;
					hsync-len = <0x08>;
					vfront-porch = <0x58>;
					vback-porch = <0x26>;
					hfront-porch = <0x8c>;
					hback-porch = <0x8c>;
					vactive = <0x780>;
					hactive = <0x4b0>;
					clock-frequency = <0xaefaec0>;
				};
			};
		};
		lcd_huaying_hx83102j_huaying_mipi_hdplus_himax {
			phandle = <0x24f>;
			sprd,sleep-out-command = [05 78 00 01 11 05 14 00 01 29];
			sprd,sleep-in-command = <0x15010002 0xac0a3914 0x32800 0x397800 0x3100000>;
			zte,initial-command-fps90 = [39 00 00 06 b9 83 10 21 55 00 39 00 00 1b b1 2c ab ab 27 e7 32 cd 43 36 36 36 36 32 8b 11 65 00 88 fa ff ff 8f ff 08 9a 33 39 00 00 10 b2 00 47 b0 80 01 22 ca 3c 4b 00 00 00 00 88 61 39 00 00 12 b4 20 20 20 20 20 20 58 58 58 58 01 71 01 00 03 05 03 39 00 00 04 b6 63 63 03 15 00 00 02 e9 cd 15 00 00 02 ba 84 15 00 00 02 e9 3f 39 00 00 03 bc 1b 00 15 00 00 02 be 20 39 00 00 09 bf fc c4 80 9c 36 00 0d 04 39 00 00 0b c0 34 34 22 11 22 a0 31 08 f5 03 39 00 00 04 c2 43 ff 00 39 00 00 15 c7 0d 83 14 af 24 89 00 00 be 00 60 80 03 b2 04 60 10 80 22 40 15 00 00 02 e9 c6 15 00 00 02 c8 97 15 00 00 02 e9 3f 39 00 00 06 c9 00 1e 10 40 01 39 00 00 07 cb 08 13 07 00 08 9f 39 00 00 04 cc 0e 03 4c 15 00 00 02 e9 c4 15 00 00 02 d0 03 15 00 00 02 e9 3f 39 00 00 08 d1 37 06 00 02 04 2c ff 15 00 00 02 d2 01 39 00 00 23 d3 06 00 00 00 00 08 08 08 08 47 07 74 37 20 20 03 03 32 10 1c 00 1c 32 17 ab 07 ab 32 10 08 00 08 00 00 39 00 00 2d d5 25 25 24 24 19 19 18 18 18 18 1e 1e 1f 1f 18 18 00 00 01 01 02 02 03 03 04 04 05 05 06 06 07 07 21 21 20 20 18 18 18 18 18 18 18 18 39 00 00 2d d6 20 20 21 21 18 18 19 19 18 18 1e 1e 1f 1f 40 40 07 07 06 06 05 05 04 04 03 03 02 02 01 01 00 00 24 24 25 25 40 40 18 18 18 18 18 18 39 00 00 25 d8 00 00 00 00 00 00 00 00 00 00 00 00 00 00 00 00 00 00 00 00 00 00 00 00 00 00 00 00 00 00 00 00 00 00 00 00 39 00 00 2e e1 11 00 00 89 30 80 07 80 02 58 00 28 02 58 02 58 02 00 02 2c 00 20 04 12 00 08 00 0c 02 77 02 4a 18 00 10 f0 03 0c 20 00 06 0b 0b 33 0e 39 00 00 1c e7 26 0a 0a 39 33 5d 01 35 5d 14 14 00 00 00 00 9c 0c 01 02 00 33 02 04 18 01 69 77 15 00 00 02 bd 01 39 00 00 05 b1 01 7f 11 fd 15 00 00 02 cb 80 15 00 00 02 e9 c5 39 00 00 08 d3 20 00 00 80 80 0c 81 15 00 00 02 e9 3f 39 00 00 1a e1 40 09 be 19 fc 19 fa 19 f8 1a 38 1a 78 1a b6 2a f6 2b 34 2b 74 3b 74 6b f4 39 00 00 0c e7 01 00 b4 01 c8 09 b4 0a a0 00 04 15 00 00 02 bd 02 39 00 00 06 cb 03 07 00 09 67 15 00 00 02 bf f2 39 00 00 0d d8 ff fe ff ff fa b0 ff fe ff ff fa b0 39 00 00 19 e7 fd 03 fd 03 fd 03 02 02 02 06 00 06 81 02 40 00 20 73 01 00 03 02 01 00 15 00 00 02 bd 03 39 00 00 19 d8 aa aa aa aa aa aa a0 aa aa aa aa aa a0 ff fe ff ff fa b0 ff fe ff ff fa 15 00 00 02 e1 01 15 00 00 02 e9 c6 39 00 00 04 b4 03 ff f8 15 00 00 02 e9 3f 15 00 00 02 bd 00 15 00 00 02 e9 c4 15 00 00 02 ba 96 15 00 00 02 e9 3f 15 00 00 02 bd 01 15 00 00 02 e9 c5 15 00 00 02 ba 4f 15 00 00 02 e9 3f 15 00 00 02 bd 00 39 00 00 03 51 00 00 15 00 00 02 53 24 15 00 00 02 55 00 05 64 00 01 11 05 14 00 01 29];
			sprd,initial-command = [39 00 00 06 b9 83 10 21 55 00 39 00 00 1b b1 2c ab ab 27 e7 32 cd 43 36 36 36 36 32 8b 11 65 00 88 fa ff ff 8f ff 08 9a 33 39 00 00 10 b2 00 47 b0 80 01 22 ca 3c 4b 00 00 00 00 88 61 39 00 00 12 b4 20 20 20 20 20 20 58 58 58 58 01 71 01 00 03 05 03 39 00 00 04 b6 63 63 03 15 00 00 02 e9 cd 15 00 00 02 ba 84 15 00 00 02 e9 3f 39 00 00 03 bc 1b 00 15 00 00 02 be 20 39 00 00 09 bf fc c4 80 9c 36 00 0d 04 39 00 00 0b c0 34 34 22 11 22 a0 31 08 f5 03 39 00 00 04 c2 43 ff 00 39 00 00 15 c7 0d 83 14 af 24 89 00 00 be 00 60 80 03 b2 04 60 10 80 22 40 15 00 00 02 e9 c6 15 00 00 02 c8 97 15 00 00 02 e9 3f 39 00 00 06 c9 00 1e 10 40 01 39 00 00 07 cb 08 13 07 00 08 9f 39 00 00 04 cc 0e 03 4c 15 00 00 02 e9 c4 15 00 00 02 d0 03 15 00 00 02 e9 3f 39 00 00 08 d1 37 06 00 02 04 2c ff 15 00 00 02 d2 01 39 00 00 23 d3 06 00 00 00 00 08 08 08 08 47 07 74 37 20 20 03 03 32 10 1c 00 1c 32 17 ab 07 ab 32 10 08 00 08 00 00 39 00 00 2d d5 25 25 24 24 19 19 18 18 18 18 1e 1e 1f 1f 18 18 00 00 01 01 02 02 03 03 04 04 05 05 06 06 07 07 21 21 20 20 18 18 18 18 18 18 18 18 39 00 00 2d d6 20 20 21 21 18 18 19 19 18 18 1e 1e 1f 1f 40 40 07 07 06 06 05 05 04 04 03 03 02 02 01 01 00 00 24 24 25 25 40 40 18 18 18 18 18 18 39 00 00 25 d8 00 00 00 00 00 00 00 00 00 00 00 00 00 00 00 00 00 00 00 00 00 00 00 00 00 00 00 00 00 00 00 00 00 00 00 00 39 00 00 2e e1 11 00 00 89 30 80 07 80 02 58 00 28 02 58 02 58 02 00 02 2c 00 20 04 12 00 08 00 0c 02 77 02 4a 18 00 10 f0 03 0c 20 00 06 0b 0b 33 0e 39 00 00 1c e7 26 0a 0a 39 33 5d 01 35 5d 14 14 00 00 00 00 9c 0c 01 02 00 33 02 04 18 01 69 77 15 00 00 02 bd 01 39 00 00 05 b1 01 7f 11 fd 15 00 00 02 cb 80 15 00 00 02 e9 c5 39 00 00 08 d3 20 00 00 80 80 0c 81 15 00 00 02 e9 3f 39 00 00 1a e1 40 09 be 19 fc 19 fa 19 f8 1a 38 1a 78 1a b6 2a f6 2b 34 2b 74 3b 74 6b f4 39 00 00 0c e7 01 00 b4 01 c8 09 b4 0a a0 00 04 15 00 00 02 bd 02 39 00 00 06 cb 03 07 00 09 67 15 00 00 02 bf f2 39 00 00 0d d8 ff fe ff ff fa b0 ff fe ff ff fa b0 39 00 00 19 e7 fd 03 fd 03 fd 03 02 02 02 06 00 06 81 02 40 00 20 73 01 00 03 02 01 00 15 00 00 02 bd 03 39 00 00 19 d8 aa aa aa aa aa aa a0 aa aa aa aa aa a0 ff fe ff ff fa b0 ff fe ff ff fa 15 00 00 02 e1 01 15 00 00 02 e9 c6 39 00 00 04 b4 03 ff f8 15 00 00 02 e9 3f 15 00 00 02 bd 00 15 00 00 02 e9 c4 15 00 00 02 ba 96 15 00 00 02 e9 3f 15 00 00 02 bd 01 15 00 00 02 e9 c5 15 00 00 02 ba 4f 15 00 00 02 e9 3f 15 00 00 02 bd 00 39 00 00 03 51 00 00 15 00 00 02 53 24 15 00 00 02 55 00 05 64 00 01 11 05 14 00 01 29];
			sprd,use-gen-write;
			sprd,reset-off-sequence = <0x01 0x14>;
			sprd,reset-on-sequence = <0x01 0x05 0x00 0x02 0x01 0x0b>;
			sprd,dphy-taget-val = <0x05>;
			sprd,esd-check-value = <0x9c>;
			sprd,esd-check-register = <0x0a>;
			sprd,esd-check-period = <0x7d0>;
			sprd,esd-check-mode = <0x01>;
			sprd,esd-check-enable = <0x00>;
			sprd,height-mm = <0x39960>;
			sprd,width-mm = <0x23fdc>;
			sprd,phy-escape-clock = <0x4e20>;
			sprd,phy-bit-clock = <0xdac00>;
			sprd,dual-dsi-enable = <0x00>;
			sprd,dsc-enable = <0x01>;
			sprd,output-bpc = <0x08>;
			sprd,slice-height = <0x28>;
			sprd,slice-width = <0x258>;
			sprd,hporch-lp-disable = <0x00>;
			sprd,video-lp-cmd-enable = <0x00>;
			sprd,dpi-clk-div = <0x00>;
			sprd,dsi-color-format = "dsc";
			sprd,dsi-lane-number = <0x04>;
			sprd,dsi-work-mode = <0x01>;
			zte,lcd-disable-mipi-hop;
			zte,lcd-version-v000;
			zte,lcd-delay-open-bl-value = <0x64>;
			zte,panel-name = "lcd_huaying_hx83102j_huaying_mipi_hdplus_himax";
			zte,lcd-disable-ssc;
			zte,lcd_bl_vsp_vsn_voltage = <0x14>;
			zte,lcm_backlight_curve_mode = "lcd_brightness_max_450_lux";
			zte,lcd-backlight-register-bit-length = <0x0c>;
			zte,lcd-init-code-version = "20240102";
			oled-backlight {
				brightness-levels = [39 00 00 03 51 00 00 39 00 00 02 53 2c];
				sprd,max-level = <0xfff>;
				default-brightness-level = <0x666>;
			};
			display-timings {
				native-mode = <0x233>;
				timing1 {
					phandle = <0x250>;
					vsync-len = <0x08>;
					hsync-len = <0x04>;
					vfront-porch = <0x120>;
					vback-porch = <0x1c>;
					hfront-porch = <0x9c>;
					hback-porch = <0xa0>;
					vactive = <0x780>;
					hactive = <0x4b0>;
					clock-frequency = <0x124f8000>;
				};
				timing0 {
					phandle = <0x233>;
					vsync-len = <0x08>;
					hsync-len = <0x04>;
					vfront-porch = <0x580>;
					vback-porch = <0x1c>;
					hfront-porch = <0x9c>;
					hback-porch = <0xa0>;
					vactive = <0x780>;
					hactive = <0x4b0>;
					clock-frequency = <0x124f8000>;
				};
			};
		};
		lcd_lead_hx83102j_hsd_mipi_hdplus_himax {
			phandle = <0x24d>;
			sprd,sleep-out-command = [05 78 00 01 11 05 14 00 01 29];
			sprd,sleep-in-command = <0x15010002 0xac0a3914 0x32800 0x397800 0x3100000>;
			zte,initial-command-fps90 = <0x39000006 0xb9831021 0x55003900 0x5d900 0x102d139 0x1bb1 0x2cadad29 0xe943dc43 0x21212121 0x1a8b1165 0x88faff 0xff8fff08 0x88333900 0x18b200 0x47b08001 0x268e3c4e 0x3030200 0x88f52287 0x13 0x50a03900 0xdb46a 0x386a386a 0x386a3858 0x4c013a39 0x2e9 0xcd390000 0x2ba8439 0x2e9 0x3f390000 0x3bc1d04 0x39000002 0xbe203900 0x3bffc 0xc4390000 0xbc03636 0x221122a0 0x6108f503 0x39000015 0xc70d8314 0xaf248b00 0xbe0060 0x8003b204 0x60108022 0x40390000 0x2e9c639 0x2c8 0x97390000 0x2e93f39 0x6c9 0x1e1388 0x1390000 0x7cb0813 0x70008d3 0x39000004 0xcc0e034c 0x39000002 0xe9c43900 0x2d003 0x39000002 0xe93f3900 0x8d137 0x6000204 0x2cff3900 0x23d306 0x00 0x80008 0x3747343b 0x27270303 0x32102500 0x25321008 0x83217 0xa907a900 0x390000 0x2dd51818 0x18181818 0x18181818 0x19191818 0x1a1a1b1b 0x10203 0x4050607 0x20212829 0x18181818 0x18181818 0x18181818 0x18183900 0x2dd618 0x18181818 0x18181818 0x18181819 0x191a1a1b 0x1b070605 0x4030201 0x292821 0x20181818 0x18181818 0x18181818 0x18181839 0x25d8 0xaabaeaaa 0xaaa0aaba 0xeaaaaaa0 0xaabaeaaa 0xaaa0aaba 0xeaaaaaa0 0xaabaeaaa 0xaaa0aaba 0xeaaaaaa0 0x3900002d 0xe1110000 0x89308007 0x80025800 0x14025802 0x58020002 0x2c002002 0x2000800 0xc050e04 0x94180010 0xf0030c20 0x60b0b 0x33390000 0x2fe00005 0x131e2848 0x626a716c 0x868a8c9a 0x959ba2b3 0xb0565d66 0x73000513 0x1e284862 0x6a716c86 0x8a8c9a95 0x9ba2b3b0 0x565d6673 0x3900001c 0xe70d0e0e 0x34445d02 0x925d1414 0x00 0x42070102 0x330384 0x18016977 0x39000002 0xbd013900 0x5b101 0x7f11fd39 0x2cb 0x80390000 0x3d25afa 0x3900000c 0xd3000044 0x00 0x800c01 0x39000002 0xe9d13900 0xae1f6 0x2b342b74 0x3b746bf4 0x39000002 0xe93f3900 0x29e701 0x3b019a 0xd2e0ea0 0x2040 0x50400048 0x30c0404 0x00 0x7e7f0001 0x2000000 0x00 0x10239 0x2bd 0x2390000 0x9cb0200 0x11100 0x20033900 0xdd8ff 0xffbffeaa 0xa0ffffbf 0xfeaaa039 0x1de7 0xfe01fe01 0xfe010000 0x230023 0x81024000 0x20580504 0x3020100 0x100 0x39000002 0xbd033900 0x2e9c6 0x39000004 0xb403fff8 0x39000002 0xe93f3900 0x25d800 0x2aaaaaaa 0xa0002aaa 0xaaaaa000 0x3fffffff 0xf0003fff 0xfffff000 0x2aaaaaaa 0xa0002aaa 0xaaaaa039 0x2e1 0x1390000 0x2bd0039 0x2e9 0xc4390000 0x2ba9639 0x2e9 0x3f390000 0x2bd0139 0x2e9 0xc5390000 0x2ba4f39 0x2e9 0x3f390000 0x2bd0039 0x6b9 0x00 0x390000 0x3510000 0x39000002 0x35003900 0x25324 0x39000002 0x55000564 0x11105 0x14000129>;
			sprd,initial-command = <0x39000006 0xb9831021 0x55003900 0x5d900 0x102d139 0x1bb1 0x2cadad29 0xe943dc43 0x21212121 0x1a8b1165 0x88faff 0xff8fff08 0x88333900 0x18b200 0x47b08001 0x268e3c4e 0x3030200 0x88f72287 0x13 0x50a03900 0xdb46a 0x386a386a 0x386a3858 0x4c013a39 0x2e9 0xcd390000 0x2ba8439 0x2e9 0x3f390000 0x3bc1d04 0x39000002 0xbe203900 0x3bffc 0xc4390000 0xbc03636 0x221122a0 0x6108f503 0x39000015 0xc70d8314 0xaf248b00 0xbe0060 0x8003b204 0x60108022 0x40390000 0x2e9c639 0x2c8 0x97390000 0x2e93f39 0x6c9 0x1e1388 0x1390000 0x7cb0813 0x70008d3 0x39000004 0xcc0e034c 0x39000002 0xe9c43900 0x2d003 0x39000002 0xe93f3900 0x8d137 0x6000204 0x2cff3900 0x23d306 0x00 0x80008 0x3747343b 0x27270303 0x32102500 0x25321008 0x83217 0xa907a900 0x390000 0x2dd51818 0x18181818 0x18181818 0x19191818 0x1a1a1b1b 0x10203 0x4050607 0x20212829 0x18181818 0x18181818 0x18181818 0x18183900 0x2dd618 0x18181818 0x18181818 0x18181819 0x191a1a1b 0x1b070605 0x4030201 0x292821 0x20181818 0x18181818 0x18181818 0x18181839 0x25d8 0xaabaeaaa 0xaaa0aaba 0xeaaaaaa0 0xaabaeaaa 0xaaa0aaba 0xeaaaaaa0 0xaabaeaaa 0xaaa0aaba 0xeaaaaaa0 0x3900002d 0xe1110000 0x89308007 0x80025800 0x14025802 0x58020002 0x2c002002 0x2000800 0xc050e04 0x94180010 0xf0030c20 0x60b0b 0x33390000 0x2fe00005 0x131e2848 0x626a716c 0x868a8c9a 0x959ba2b3 0xb0565d66 0x73000513 0x1e284862 0x6a716c86 0x8a8c9a95 0x9ba2b3b0 0x565d6673 0x3900001c 0xe70d0e0e 0x34445d02 0x925d1414 0x00 0x42070102 0x330384 0x18016977 0x39000002 0xbd013900 0x5b101 0x7f11fd39 0x2cb 0x80390000 0x3d25afa 0x3900000c 0xd3000044 0x00 0x800c01 0x39000002 0xe9d13900 0xae1f6 0x2b342b74 0x3b746bf4 0x39000002 0xe93f3900 0x29e701 0x3b019a 0xd2e0ea0 0x2040 0x50400048 0x30c0404 0x00 0x7e7f0001 0x2000000 0x00 0x10239 0x2bd 0x2390000 0x9cb0200 0x11100 0x20033900 0xdd8ff 0xffbffeaa 0xa0ffffbf 0xfeaaa039 0x1de7 0xfe01fe01 0xfe010000 0x230023 0x81024000 0x20580504 0x3020100 0x100 0x39000002 0xbd033900 0x2e9c6 0x39000004 0xb403fff8 0x39000002 0xe93f3900 0x25d800 0x2aaaaaaa 0xa0002aaa 0xaaaaa000 0x3fffffff 0xf0003fff 0xfffff000 0x2aaaaaaa 0xa0002aaa 0xaaaaa039 0x2e1 0x1390000 0x2bd0039 0x2e9 0xc4390000 0x2ba9639 0x2e9 0x3f390000 0x2bd0139 0x2e9 0xc5390000 0x2ba4f39 0x2e9 0x3f390000 0x2bd0039 0x6b9 0x00 0x390000 0x3510000 0x39000002 0x35003900 0x25324 0x39000002 0x55000564 0x11105 0x14000129>;
			sprd,use-gen-write;
			sprd,reset-off-sequence = <0x01 0x14>;
			sprd,reset-on-sequence = <0x01 0x05 0x00 0x02 0x01 0x14>;
			sprd,dphy-taget-val = <0x05>;
			sprd,esd-check-value = <0x9c>;
			sprd,esd-check-register = <0x0a>;
			sprd,esd-check-period = <0x7d0>;
			sprd,esd-check-mode = <0x01>;
			sprd,esd-check-enable = <0x01>;
			sprd,height-mm = <0x39960>;
			sprd,width-mm = <0x23fdc>;
			sprd,phy-escape-clock = <0x4e20>;
			sprd,phy-bit-clock = <0xdac00>;
			sprd,dual-dsi-enable = <0x00>;
			sprd,dsc-enable = <0x01>;
			sprd,output-bpc = <0x08>;
			sprd,slice-height = <0x14>;
			sprd,slice-width = <0x258>;
			sprd,hporch-lp-disable = <0x00>;
			sprd,video-lp-cmd-enable = <0x00>;
			sprd,dpi-clk-div = <0x00>;
			sprd,dsi-color-format = "dsc";
			sprd,dsi-lane-number = <0x04>;
			sprd,dsi-work-mode = <0x01>;
			zte,lcd-disable-mipi-hop;
			zte,lcd-version-v000;
			zte,lcd-delay-open-bl-value = <0x64>;
			zte,panel-name = "lcd_lead_hx83102j_hsd_mipi_hdplus_himax";
			zte,lcd-disable-ssc;
			zte,lcd_bl_vsp_vsn_voltage = <0x14>;
			zte,lcm_backlight_curve_mode = "lcd_brightness_max_450_lux";
			zte,lcd-backlight-register-bit-length = <0x0c>;
			zte,lcd-init-code-version = "20240604";
			oled-backlight {
				brightness-levels = [39 00 00 03 51 00 00 39 00 00 02 53 2c];
				sprd,max-level = <0xfff>;
				default-brightness-level = <0x666>;
			};
			display-timings {
				native-mode = <0x232>;
				timing1 {
					phandle = <0x24e>;
					vsync-len = <0x08>;
					hsync-len = <0x08>;
					vfront-porch = <0x190>;
					vback-porch = <0x20>;
					hfront-porch = <0x88>;
					hback-porch = <0x64>;
					vactive = <0x780>;
					hactive = <0x4b0>;
					clock-frequency = <0x124f8000>;
				};
				timing0 {
					phandle = <0x232>;
					vsync-len = <0x08>;
					hsync-len = <0x08>;
					vfront-porch = <0x624>;
					vback-porch = <0x20>;
					hfront-porch = <0x88>;
					hback-porch = <0x64>;
					vactive = <0x780>;
					hactive = <0x4b0>;
					clock-frequency = <0x124f8000>;
				};
			};
		};
		lcd_lead_icnl9951r_hsd_mipi_hdplus_chipone {
			phandle = <0x24b>;
			sprd,sleep-out-command = [05 78 00 01 11 05 14 00 01 29];
			sprd,sleep-in-command = <0x15010002 0xac0a3914 0x32800 0x397800 0x3100000>;
			zte,initial-command-fps90 = [39 00 00 03 f0 5a 59 39 00 00 03 f1 a5 a6 39 00 00 21 b2 03 85 02 86 33 33 09 03 66 51 51 51 51 51 51 51 51 51 51 51 51 00 00 00 00 00 00 00 55 11 00 00 39 00 00 21 b3 73 01 01 01 81 4b 00 00 51 00 00 11 34 01 01 01 01 00 00 00 00 00 00 00 03 06 80 80 01 00 00 00 39 00 00 21 b4 0d 1f 0d 1f 56 26 01 3b bb eb fa dc a0 87 80 01 02 13 20 30 05 90 23 20 40 11 10 20 00 00 00 00 39 00 00 21 b5 03 03 03 03 03 00 01 a8 a9 13 11 0f 0d 25 24 00 00 00 00 00 00 00 00 30 c0 00 00 00 ff ff fc 00 39 00 00 21 b6 03 03 03 03 03 00 01 a8 a9 12 10 0e 0c 23 22 00 00 00 00 00 00 00 00 30 c0 00 00 00 ff ff fc 00 39 00 00 1f b7 00 03 00 00 00 00 00 03 00 00 00 00 00 00 00 00 00 00 00 00 00 00 00 00 00 30 c0 00 00 00 39 00 00 1f b8 00 03 00 00 00 00 00 03 00 00 00 00 00 00 00 00 00 00 00 00 00 00 00 00 00 30 c0 00 00 00 39 00 00 21 b9 01 55 55 55 55 55 50 55 55 55 55 55 50 00 00 00 00 00 00 00 00 00 00 00 00 00 00 00 00 00 00 00 39 00 00 10 bb 01 02 03 0a 04 13 14 12 16 5c 00 15 16 03 00 39 00 00 1a bc fe f8 f0 00 00 00 00 04 00 05 80 02 24 00 99 99 99 00 c4 09 c3 86 03 2e 11 39 00 00 09 bd ec 23 42 52 52 1f 00 00 39 00 00 18 be 6e 46 79 47 0a 88 58 33 33 33 93 00 e5 e5 00 00 00 00 b2 af b2 af 00 39 00 00 0b bf 0c 19 0c 19 00 11 22 04 5d 07 39 00 00 17 c0 40 90 17 12 34 f5 67 89 ff ff ff ff ff 3f 00 ff 00 cc 02 00 01 14 39 00 00 17 c1 01 20 00 26 00 20 04 9c a0 04 c7 80 0f 0d c0 22 7f cf ff ff 0f e7 39 00 00 09 c2 11 05 01 10 00 01 00 80 39 00 00 21 c3 00 ff 42 4d 01 00 00 00 00 00 00 00 00 53 10 10 2a 2a 2a 2a 2a 2a 2a 2a 40 00 00 00 00 00 00 00 39 00 00 0f c4 0c 35 28 49 00 3f 00 50 00 1f 00 22 f0 ef 39 00 00 21 c5 03 13 10 56 5d 38 04 05 08 04 19 00 b4 2c 2b 2b bb ac 20 00 02 00 80 0f 0f 06 13 64 ff 03 20 ff 39 00 00 1e c7 76 54 32 22 34 56 77 77 20 76 54 32 22 34 56 77 77 20 42 00 21 ff ff 04 04 03 0e 07 00 39 00 00 21 80 e8 cd a6 85 6b 55 42 31 22 f0 ca a6 87 6b 52 21 f2 c8 a1 9f 7a 54 2c 00 d6 9f 7c 4e 41 3a 33 29 39 00 00 21 81 e8 ca 9d 7c 63 4c 39 28 18 e8 c3 9f 80 65 4d 1b ec c3 9d 9b 76 51 29 fe d4 9e 7a 4c 40 39 32 28 39 00 00 21 82 e8 cb a1 80 67 50 3d 2c 1d ec c6 a2 83 68 4f 1e ef c5 9f 9d 78 52 2a ff d5 9e 7b 4d 40 39 32 28 39 00 00 1a 83 09 20 13 05 00 1f 12 05 00 1f 12 05 00 28 18 08 00 28 18 08 00 28 18 08 00 39 00 00 1c 84 ff ff ea aa 55 55 00 00 00 ff ff ea aa 55 54 00 00 00 ff ff ea aa 55 54 00 00 00 39 00 00 08 c8 42 00 48 e7 e0 00 23 39 00 00 07 d7 3f 04 0a 00 00 0e 39 00 00 04 d5 01 30 88 39 00 00 03 f0 5a 57 39 00 00 03 f1 a5 a7 39 00 00 0e 79 41 12 00 00 00 00 97 02 00 20 00 03 02 39 00 00 03 f0 5a 58 39 00 00 03 f1 a5 a8 39 00 00 0e 79 41 12 00 00 00 00 97 02 00 20 00 02 02 39 00 00 03 f0 5a 59 39 00 00 03 f1 a5 a6 39 00 00 21 7a 11 00 00 89 30 80 07 80 04 b0 00 08 02 58 02 58 02 00 02 2c 00 20 00 c4 00 08 00 0c 0d b7 0b 71 39 00 00 21 7b 18 00 10 f0 03 0c 20 00 06 0b 0b 33 0e 1c 2a 38 46 54 62 69 70 77 79 7b 7d 7e 01 02 01 00 09 40 39 00 00 19 7c 09 be 19 fc 19 fa 19 f8 1a 38 1a 78 1a b6 2a f6 2b 34 2b 74 3b 74 6b f4 39 00 00 1a e0 0c 00 b8 10 00 0a be 00 0b 05 01 00 1f 00 00 00 00 24 12 88 11 48 42 00 00 15 00 00 02 36 03 15 00 00 02 35 00 39 00 00 03 51 00 00 15 00 00 02 53 2c 05 64 00 01 11 05 14 00 01 29 15 00 00 02 ac 05 39 00 00 09 bd 2d 23 42 52 52 1f 00 00 39 00 00 03 f1 5a 59 39 01 00 03 f0 a5 a6];
			sprd,initial-command = [39 00 00 03 f0 5a 59 39 00 00 03 f1 a5 a6 39 00 00 21 b2 03 85 02 86 33 33 09 03 66 51 51 51 51 51 51 51 51 51 51 51 51 00 00 00 00 00 00 00 55 11 00 00 39 00 00 21 b3 73 01 01 01 81 4b 00 00 51 00 00 11 34 01 01 01 01 00 00 00 00 00 00 00 03 06 80 80 01 00 00 00 39 00 00 21 b4 0d 1f 0d 1f 56 26 01 3b bb eb fa dc a0 87 80 01 02 13 20 30 05 90 23 20 40 11 10 20 00 00 00 00 39 00 00 21 b5 03 03 03 03 03 00 01 a8 a9 13 11 0f 0d 25 24 00 00 00 00 00 00 00 00 30 c0 00 00 00 ff ff fc 00 39 00 00 21 b6 03 03 03 03 03 00 01 a8 a9 12 10 0e 0c 23 22 00 00 00 00 00 00 00 00 30 c0 00 00 00 ff ff fc 00 39 00 00 1f b7 00 03 00 00 00 00 00 03 00 00 00 00 00 00 00 00 00 00 00 00 00 00 00 00 00 30 c0 00 00 00 39 00 00 1f b8 00 03 00 00 00 00 00 03 00 00 00 00 00 00 00 00 00 00 00 00 00 00 00 00 00 30 c0 00 00 00 39 00 00 21 b9 01 55 55 55 55 55 50 55 55 55 55 55 50 00 00 00 00 00 00 00 00 00 00 00 00 00 00 00 00 00 00 00 39 00 00 10 bb 01 02 03 0a 04 13 14 12 16 5c 00 15 16 03 00 39 00 00 1a bc fe f8 f0 00 00 00 00 04 00 05 80 02 24 00 99 99 99 00 c4 09 c3 86 03 2e 11 39 00 00 09 bd ec 23 42 52 52 1f 00 00 39 00 00 18 be 6e 46 79 47 0a 88 58 33 33 33 93 00 e5 e5 00 00 00 00 b2 af b2 af 00 39 00 00 0b bf 0c 19 0c 19 00 11 22 04 5d 07 39 00 00 17 c0 40 90 17 12 34 f5 67 89 ff ff ff ff ff 3f 00 ff 00 cc 02 00 01 14 39 00 00 17 c1 01 20 00 26 00 20 04 9c a0 04 c7 80 0f 0d c0 22 7f cf ff ff 0f e7 39 00 00 09 c2 11 05 01 10 00 01 00 80 39 00 00 21 c3 00 ff 42 4d 01 00 00 00 00 00 00 00 00 53 10 10 2a 2a 2a 2a 2a 2a 2a 2a 40 00 00 00 00 00 00 00 39 00 00 0f c4 0c 35 28 49 00 3f 00 50 00 1f 00 22 f0 ef 39 00 00 21 c5 03 13 10 56 5d 38 04 05 08 04 19 00 b4 2c 2b 2b bb ac 20 00 02 00 80 0f 0f 06 13 64 ff 03 20 ff 39 00 00 1e c7 76 54 32 22 34 56 77 77 20 76 54 32 22 34 56 77 77 20 42 00 21 ff ff 04 04 03 0e 07 00 39 00 00 21 80 e8 cd a6 85 6b 55 42 31 22 f0 ca a6 87 6b 52 21 f2 c8 a1 9f 7a 54 2c 00 d6 9f 7c 4e 41 3a 33 29 39 00 00 21 81 e8 ca 9d 7c 63 4c 39 28 18 e8 c3 9f 80 65 4d 1b ec c3 9d 9b 76 51 29 fe d4 9e 7a 4c 40 39 32 28 39 00 00 21 82 e8 cb a1 80 67 50 3d 2c 1d ec c6 a2 83 68 4f 1e ef c5 9f 9d 78 52 2a ff d5 9e 7b 4d 40 39 32 28 39 00 00 1a 83 09 20 13 05 00 1f 12 05 00 1f 12 05 00 28 18 08 00 28 18 08 00 28 18 08 00 39 00 00 1c 84 ff ff ea aa 55 55 00 00 00 ff ff ea aa 55 54 00 00 00 ff ff ea aa 55 54 00 00 00 39 00 00 08 c8 42 00 48 e7 e0 00 23 39 00 00 07 d7 3f 04 0a 00 00 0e 39 00 00 04 d5 01 30 88 39 00 00 03 f0 5a 57 39 00 00 03 f1 a5 a7 39 00 00 0e 79 41 12 00 00 00 00 97 02 00 20 00 03 02 39 00 00 03 f0 5a 58 39 00 00 03 f1 a5 a8 39 00 00 0e 79 41 12 00 00 00 00 97 02 00 20 00 02 02 39 00 00 03 f0 5a 59 39 00 00 03 f1 a5 a6 39 00 00 21 7a 11 00 00 89 30 80 07 80 04 b0 00 08 02 58 02 58 02 00 02 2c 00 20 00 c4 00 08 00 0c 0d b7 0b 71 39 00 00 21 7b 18 00 10 f0 03 0c 20 00 06 0b 0b 33 0e 1c 2a 38 46 54 62 69 70 77 79 7b 7d 7e 01 02 01 00 09 40 39 00 00 19 7c 09 be 19 fc 19 fa 19 f8 1a 38 1a 78 1a b6 2a f6 2b 34 2b 74 3b 74 6b f4 39 00 00 1a e0 0c 00 b8 10 00 0a be 00 0b 05 01 00 1f 00 00 00 00 24 12 88 11 48 42 00 00 15 00 00 02 36 03 15 00 00 02 35 00 39 00 00 03 51 00 00 15 00 00 02 53 2c 05 64 00 01 11 05 14 00 01 29 15 00 00 02 ac 05 39 00 00 09 bd 2d 23 42 52 52 1f 00 00 39 00 00 03 f1 5a 59 39 01 00 03 f0 a5 a6];
			sprd,use-gen-write;
			sprd,reset-off-sequence = <0x01 0x14>;
			sprd,reset-on-sequence = <0x01 0x05 0x00 0x02 0x01 0x0b>;
			sprd,dphy-taget-val = <0x05>;
			sprd,esd-check-value = <0x9c>;
			sprd,esd-check-register = <0x0a>;
			sprd,esd-check-period = <0x7d0>;
			sprd,esd-check-mode = <0x01>;
			sprd,esd-check-enable = <0x01>;
			sprd,height-mm = <0x39960>;
			sprd,width-mm = <0x23fdc>;
			sprd,phy-escape-clock = <0x4e20>;
			sprd,phy-bit-clock = <0xdac00>;
			sprd,dual-dsi-enable = <0x00>;
			sprd,dsc-enable = <0x01>;
			sprd,output-bpc = <0x08>;
			sprd,slice-height = <0x08>;
			sprd,slice-width = <0x258>;
			sprd,hporch-lp-disable = <0x00>;
			sprd,video-lp-cmd-enable = <0x00>;
			sprd,dpi-clk-div = <0x00>;
			sprd,dsi-color-format = "dsc";
			sprd,dsi-lane-number = <0x04>;
			sprd,dsi-work-mode = <0x01>;
			zte,lcd-disable-mipi-hop;
			zte,lcd-version-v000;
			zte,lcd-delay-open-bl-value = <0x64>;
			zte,panel-name = "lcd_lead_icnl9951r_hsd_mipi_hdplus_chipone";
			zte,lcd-disable-ssc;
			zte,lcd_bl_vsp_vsn_voltage = <0x14>;
			zte,lcm_backlight_curve_mode = "lcd_brightness_max_450_lux";
			zte,lcd-backlight-register-bit-length = <0x0c>;
			zte,lcd-init-code-version = "20231206_icappwm";
			oled-backlight {
				brightness-levels = [39 00 00 03 51 00 00 39 00 00 02 53 2c];
				sprd,max-level = <0xfff>;
				default-brightness-level = <0x666>;
			};
			display-timings {
				native-mode = <0x231>;
				timing1 {
					phandle = <0x24c>;
					vsync-len = <0x04>;
					hsync-len = <0x04>;
					vfront-porch = <0x120>;
					vback-porch = <0x20>;
					hfront-porch = <0x9c>;
					hback-porch = <0xa0>;
					vactive = <0x780>;
					hactive = <0x4b0>;
					clock-frequency = <0x124f8000>;
				};
				timing0 {
					phandle = <0x231>;
					vsync-len = <0x04>;
					hsync-len = <0x04>;
					vfront-porch = <0x580>;
					vback-porch = <0x20>;
					hfront-porch = <0x9c>;
					hback-porch = <0xa0>;
					vactive = <0x780>;
					hactive = <0x4b0>;
					clock-frequency = <0x124f8000>;
				};
			};
		};
		lcd_guoxian_hx83102j_huaxing_nopen_mipi_himax {
			phandle = <0x249>;
			sprd,sleep-out-command = [05 78 00 01 11 05 14 00 01 29];
			sprd,sleep-in-command = <0x15010002 0xac0a3914 0x32800 0x397800 0x3100000>;
			zte,initial-command-fps90 = [39 00 00 06 b9 83 10 21 55 00 15 00 00 02 e9 c4 15 00 00 02 d9 d1 15 00 00 02 e9 3f 39 00 00 12 b1 2c b5 b5 31 f1 33 dc 52 3a 3a 3a 3a 32 8b 11 e5 98 15 00 00 02 e9 d9 39 00 00 03 b1 8b 33 15 00 00 02 e9 3f 39 00 00 10 b2 00 47 b0 80 01 2c b0 3c 4c 12 30 00 00 98 51 39 00 00 12 b4 48 48 48 48 48 48 4a 4c 2a 4c 01 6b 01 02 01 00 00 39 00 00 03 bc 1b 04 15 00 00 02 be 20 39 00 00 09 bf fc c4 80 9c 36 00 0d 04 39 00 00 0b c0 32 32 22 11 22 a0 31 08 f5 03 15 00 00 02 e9 cc 15 00 00 02 c7 80 15 00 00 02 e9 3f 15 00 00 02 e9 c6 15 00 00 02 c8 97 15 00 00 02 e9 3f 39 00 00 06 c9 00 1e 13 88 01 39 00 00 07 cb 08 13 07 00 08 ae 39 00 00 04 cc 02 03 4c 39 00 00 08 d1 07 06 00 02 04 2c ff 39 00 00 23 d3 06 00 00 00 40 04 08 04 08 37 07 44 37 2b 2b 03 03 32 10 22 00 0b 32 10 29 00 29 32 10 08 00 08 00 00 39 00 00 2d d5 18 18 18 18 18 18 18 18 18 18 07 06 07 06 05 04 05 04 03 02 03 02 01 00 01 00 18 18 25 24 25 24 1f 1f 1f 1f 1e 1e 1e 1e 20 20 20 20 39 00 00 0d d8 0a 2a aa 8a aa a0 0a 2a aa 8a aa a0 39 00 00 2d e1 11 00 00 89 30 80 07 80 02 58 00 14 02 58 02 58 02 00 02 2c 00 20 02 02 00 08 00 0c 05 0e 04 94 18 00 10 f0 03 0c 20 00 06 0b 0b 33 39 00 00 1c e7 12 10 10 3f 1e 9d 02 52 9d 14 14 00 00 00 00 96 0a 01 02 00 33 02 04 18 01 69 77 15 00 00 02 bd 01 39 00 00 05 b1 01 7f 11 fd 15 00 00 02 e9 c5 15 00 00 02 ba 4f 15 00 00 02 e9 3f 15 00 00 02 cb 86 15 00 00 02 d2 64 15 00 00 02 e9 c5 15 00 00 02 d3 00 15 00 00 02 e9 3f 39 00 00 19 d8 0a 2a aa 8a aa a0 0a 2a aa 8a aa a0 05 15 55 45 55 50 05 15 55 45 55 50 15 00 00 02 e9 d1 39 00 00 0a e1 f6 2b 34 2b 74 3b 74 6b f4 15 00 00 02 e9 3f 39 00 00 0c e7 01 00 24 01 7e 0f 7c 10 a0 00 00 15 00 00 02 bd 02 39 00 00 06 cb 03 07 00 09 67 39 00 00 0d d8 0f 3f ff cf ff f0 0f 3f ff cf ff f0 39 00 00 1d e7 fe 01 fe 01 fe 01 00 00 00 23 00 23 81 02 40 00 20 6b 02 01 00 00 00 00 00 00 01 00 15 00 00 02 bd 03 39 00 00 03 b2 66 81 15 00 00 02 e9 c6 39 00 00 04 b4 03 ff f8 15 00 00 02 e9 3f 39 00 00 25 d8 0a 2a aa 8a aa a0 0a 2a aa 8a aa a0 0f 2a aa 8a aa f0 0f 2a aa 8a aa f0 0a 2a aa 8a aa a0 0a 2a aa 8a aa a0 15 00 00 02 e1 01 15 00 00 02 bd 00 39 00 00 05 b9 00 00 00 00 39 00 00 03 51 00 00 39 00 00 02 35 00 39 00 00 02 53 24 39 00 00 02 55 00 05 64 00 01 11 05 14 00 01 29];
			sprd,initial-command = <0x39000006 0xb9831021 0x55001500 0x2e9c4 0x15000002 0xd9d11500 0x2e93f 0x39000012 0xb12cb5b5 0x31f133dc 0x523a3a3a 0x3a328b11 0xe5981500 0x2e9d9 0x39000003 0xb18b3315 0x2e9 0x3f390000 0x10b20047 0xb080012c 0xb03c4c12 0x30000098 0x51390000 0x12b44848 0x48484848 0x4a4c2a4c 0x16b0102 0x1000039 0x3bc 0x1b041500 0x2be20 0x39000009 0xbffcc480 0x9c36000d 0x4390000 0xbc03232 0x221122a0 0x3108f503 0x15000002 0xe9cc1500 0x2c780 0x15000002 0xe93f1500 0x2e9c6 0x15000002 0xc8971500 0x2e93f 0x39000006 0xc9001e13 0x88013900 0x7cb08 0x13070008 0xae390000 0x4cc0203 0x4c390000 0x8d10706 0x2042c 0xff390000 0x23d30600 0x4004 0x8040837 0x744372b 0x2b030332 0x1022000b 0x32102900 0x29321008 0x80000 0x3900002d 0xd5181818 0x18181818 0x18181807 0x6070605 0x4050403 0x2030201 0x10018 0x18252425 0x241f1f1f 0x1f1e1e1e 0x1e202020 0x20390000 0xdd80a2a 0xaa8aaaa0 0xa2aaa8a 0xaaa03900 0x2de111 0x8930 0x80078002 0x58001402 0x58025802 0x22c00 0x20020200 0x8000c05 0xe049418 0x10f003 0xc200006 0xb0b3339 0x1ce7 0x1210103f 0x1e9d0252 0x9d141400 0x96 0xa010200 0x33020418 0x1697739 0x2fe0 0xa1821 0x2a4b6469 0x6f688082 0x85918d93 0x9aabaa53 0x5b667300 0xb18212a 0x4b64696f 0x68808285 0x918d939a 0xacaa535b 0x67731500 0x2bd01 0x39000005 0xb1017f11 0xfd150000 0x2e9c515 0x2ba 0x4f150000 0x2e93f15 0x2cb 0x86150000 0x2d26415 0x2e9 0xc5150000 0x2d30015 0x2e9 0x3f390000 0x19d80a2a 0xaa8aaaa0 0xa2aaa8a 0xaaa00515 0x55455550 0x5155545 0x55501500 0x2e9d1 0x3900000a 0xe1f62b34 0x2b743b74 0x6bf41500 0x2e93f 0x3900000c 0xe7010024 0x17e0f7c 0x10a00000 0x15000002 0xbd023900 0x6cb03 0x7000967 0x3900000d 0xd80f3fff 0xcffff00f 0x3fffcfff 0xf0390000 0x1de7fe01 0xfe01fe01 0x23 0x238102 0x4000206b 0x2010000 0x00 0x1001500 0x2bd03 0x39000003 0xb2668115 0x2e9 0xc6390000 0x4b403ff 0xf8150000 0x2e93f39 0x25d8 0xa2aaa8a 0xaaa00a2a 0xaa8aaaa0 0xf2aaa8a 0xaaf00f2a 0xaa8aaaf0 0xa2aaa8a 0xaaa00a2a 0xaa8aaaa0 0x15000002 0xe1011500 0x2bd00 0x39000005 0xb9000000 0x390000 0x3510000 0x39000002 0x35003900 0x25324 0x39000002 0x55000564 0x11105 0x14000129>;
			sprd,use-gen-write;
			sprd,reset-off-sequence = <0x01 0x14>;
			sprd,reset-on-sequence = <0x01 0x05 0x00 0x02 0x01 0x37>;
			sprd,dphy-taget-val = <0x05>;
			sprd,esd-check-value = <0x9c>;
			sprd,esd-check-register = <0x0a>;
			sprd,esd-check-period = <0x7d0>;
			sprd,esd-check-mode = <0x01>;
			sprd,esd-check-enable = <0x01>;
			sprd,height-mm = <0x39960>;
			sprd,width-mm = <0x23fdc>;
			sprd,phy-escape-clock = <0x4e20>;
			sprd,phy-bit-clock = <0xdac00>;
			sprd,dual-dsi-enable = <0x00>;
			sprd,dsc-enable = <0x01>;
			sprd,output-bpc = <0x08>;
			sprd,slice-height = <0x14>;
			sprd,slice-width = <0x258>;
			sprd,hporch-lp-disable = <0x00>;
			sprd,video-lp-cmd-enable = <0x00>;
			sprd,dpi-clk-div = <0x00>;
			sprd,dsi-color-format = "dsc";
			sprd,dsi-lane-number = <0x04>;
			sprd,dsi-work-mode = <0x01>;
			zte,lcd-disable-mipi-hop;
			zte,lcd-version-v000;
			zte,lcd-delay-open-bl-value = <0x64>;
			zte,panel-name = "lcd_guoxian_hx83102j_huaxing_nopen_mipi_himax";
			zte,lcd-disable-ssc;
			zte,lcd_bl_vsp_vsn_voltage = <0x14>;
			zte,lcm_backlight_curve_mode = "lcd_brightness_max_450_lux";
			zte,lcd-backlight-register-bit-length = <0x0c>;
			zte,lcd-init-code-version = "20250121";
			oled-backlight {
				brightness-levels = [39 00 00 03 51 00 00 39 00 00 02 53 2c];
				sprd,max-level = <0xfff>;
				default-brightness-level = <0x666>;
			};
			display-timings {
				native-mode = <0x230>;
				timing1 {
					phandle = <0x24a>;
					vsync-len = <0x08>;
					hsync-len = <0x04>;
					vfront-porch = <0x120>;
					vback-porch = <0x1c>;
					hfront-porch = <0x9c>;
					hback-porch = <0xa0>;
					vactive = <0x780>;
					hactive = <0x4b0>;
					clock-frequency = <0x124f8000>;
				};
				timing0 {
					phandle = <0x230>;
					vsync-len = <0x08>;
					hsync-len = <0x04>;
					vfront-porch = <0x580>;
					vback-porch = <0x1c>;
					hfront-porch = <0x9c>;
					hback-porch = <0xa0>;
					vactive = <0x780>;
					hactive = <0x4b0>;
					clock-frequency = <0x124f8000>;
				};
			};
		};
	};
	soc {
		ap-ahb {
			i2c@22a0000 {
				ti65132b@3e {
					zte,lcd-bl-vsp-vsn-enhance-enable;
					zte,tps65132b_enhance_value = <0xffff>;
					reg = <0x3e>;
					compatible = "tps,ti65132b";
				};
			};
		};
		dpuvsp {
			dpu@31000000 {
				sprd,backlight = <0x23e>;
				sprd,logo-memory = <0x23f>;
				compatible = "sprd,qogirn6pro-dpu";
				reg = <0x00 0x31000000 0x00 0x3000 0x00 0x30120000 0x00 0x100>;
				reset-syscon = <0x2d 0x04 0x01>;
				vau_reset-syscon = <0x2d 0x04 0x40000>;
				interrupts = <0x00 0x98 0x04>;
				status = "okay";
				iommus = <0x2e>;
				#power-domain-cells = <0x00>;
				power-domains = <0x2f>;
				clock-names = "clk_src_256m", "clk_src_307m2", "clk_src_312m5", "clk_src_384m", "clk_src_409m6", "clk_src_416m7", "clk_src_512m", "clk_src_614m4", "clk_dpu_core", "clk_dpu_dpi", "clk_dpuvsp_eb", "clk_dpuvsp_disp_eb", "clk_master_div6_eb";
				clocks = <0x0b 0x0c 0x0b 0x0d 0x30 0x0b 0x0e 0x0b 0x15 0x31 0x0b 0x0f 0x0b 0x16 0x32 0x06 0x32 0x07 0x11 0x0f 0x33 0x00 0x33 0x0b>;
				phandle = <0x157>;
				port {
					phandle = <0x130>;
					endpoint {
						remote-endpoint = <0x34>;
						phandle = <0x39>;
					};
				};
			};
			iommu@31001800 {
				compatible = "unisoc,iommuvaul6p-dispc";
				reg = <0x00 0x31000000 0x00 0x80 0x00 0x31001800 0x00 0x80>;
				iova-base = <0x10000000>;
				iova-size = <0x10000000>;
				reg_name = "mmu_reg";
				status = "okay";
				#iommu-cells = <0x00>;
				phandle = <0x2e>;
			};
			gsp@31100000 {
				compatible = "sprd,gsp-core";
				reg = <0x00 0x31100000 0x00 0x2000>;
				core-id = <0x00>;
				kcfg-num = <0x10>;
				interrupts = <0x00 0x97 0x04>;
				iommus = <0x35>;
				clock-names = "clk_src_512m", "clk_gsp0_eb", "clk_dpuvsp_eb", "clk_gsp0";
				clocks = <0x0b 0x0f 0x33 0x06 0x11 0x0f 0x32 0x04>;
				sprd,pmu-apb = <0x04>;
				phandle = <0x103>;
			};
			iommu@31100000 {
				compatible = "unisoc,iommuvaul6p-gsp";
				reg = <0x00 0x31100000 0x00 0x80 0x00 0x31101000 0x00 0x80>;
				iova-base = <0x20000000>;
				iova-size = <0x10000000>;
				reg_name = "mmu_reg";
				status = "okay";
				#iommu-cells = <0x00>;
				phandle = <0x35>;
			};
			gsp@31200000 {
				compatible = "sprd,gsp-core";
				reg = <0x00 0x31200000 0x00 0x2000>;
				core-id = <0x00>;
				kcfg-num = <0x10>;
				interrupts = <0x00 0x96 0x04>;
				iommus = <0x36>;
				clock-names = "clk_src_512m", "clk_gsp1_eb", "clk_dpuvsp_eb", "clk_gsp1";
				clocks = <0x0b 0x0f 0x33 0x07 0x11 0x0f 0x32 0x05>;
				phandle = <0x104>;
			};
			iommu@31200000 {
				compatible = "unisoc,iommuvaul6p-gsp1";
				reg = <0x00 0x31200000 0x00 0x80 0x00 0x31201000 0x00 0x80>;
				iova-base = <0x40000000>;
				iova-size = <0x10000000>;
				reg_name = "mmu_reg";
				status = "okay";
				#iommu-cells = <0x00>;
				phandle = <0x36>;
			};
			dsi@31300000 {
				compatible = "sprd,qogirn6pro-dsi-host";
				reg = <0x00 0x31300000 0x00 0x1000>;
				reset-syscon = <0x2d 0x04 0x02>;
				interrupts = <0x00 0x9e 0x04 0x00 0x9d 0x04>;
				status = "okay";
				#power-domain-cells = <0x00>;
				power-domains = <0x2f>;
				clock-names = "clk_dsi0_eb", "clk_dpu_dpi", "clk_src_384m", "clk_dpuvsp_eb", "clk_dpuvsp_disp_eb", "clk_master_div6_eb";
				clocks = <0x33 0x01 0x32 0x07 0x0b 0x0e 0x11 0x0f 0x33 0x00 0x33 0x0b>;
				#address-cells = <0x01>;
				#size-cells = <0x00>;
				sprd,dual-channel = <0x37>;
				phandle = <0x158>;
				ports {
					#address-cells = <0x01>;
					#size-cells = <0x00>;
					port@0 {
						reg = <0x00>;
						endpoint {
							remote-endpoint = <0x38>;
							phandle = <0x3e>;
						};
					};
					port@1 {
						reg = <0x01>;
						endpoint {
							remote-endpoint = <0x39>;
							phandle = <0x34>;
						};
					};
				};
				panel {
					sprd,backlight = <0x23e>;
					reset-gpio = <0x0c 0x0b 0x00>;
					avee-gpio = <0x0c 0xbe 0x00>;
					avdd-gpio = <0x0c 0xbd 0x00>;
					iovdd-gpio = <0x0c 0x94 0x00>;
					compatible = "sprd,generic-mipi-panel";
					#address-cells = <0x01>;
					#size-cells = <0x00>;
					reg = <0x00>;
					sprd,dual-channel = <0x37>;
					phandle = <0x159>;
					port@1 {
						reg = <0x01>;
						endpoint {
							remote-endpoint = <0x3a>;
							phandle = <0x3d>;
						};
					};
				};
			};
			dsi1@31400000 {
				compatible = "sprd,qogirn6pro-dsi1-host";
				reg = <0x00 0x31400000 0x00 0x1000>;
				reset = <0x2d 0x04 0x04>;
				syscon-names = "reset";
				interrupts = <0x00 0x9b 0x04 0x00 0x9a 0x04>;
				status = "okay";
				dev-id = <0x01>;
				sprd,ip = "sprd,dsi-ctrl", "r3p1";
				sprd,soc = "qogirn6pro_s";
				clock-names = "clk_dsi1_eb";
				clocks = <0x33 0x02>;
				phandle = <0x37>;
				ports {
					#address-cells = <0x01>;
					#size-cells = <0x00>;
					port@0 {
						reg = <0x00>;
						endpoint {
							remote-endpoint = <0x3b>;
							phandle = <0x3f>;
						};
					};
				};
			};
			dphy {
				compatible = "sprd,qogirn6pro-dsi-phy";
				#address-cells = <0x01>;
				#size-cells = <0x00>;
				reg = <0x00 0x31300000 0x00 0x1000>;
				enable-syscon = <0x2d 0x1c 0x03>;
				power-syscon = <0x04 0x9c 0x40>;
				aod_mode-syscon = <0x02 0xc30 0x2e00>;
				aod_pd-syscon = <0x02 0xc30 0x1000>;
				status = "okay";
				sprd,mipi-drive-capability = <0x07>;
				sprd,dual-channel = <0x3c>;
				phandle = <0x15a>;
				ports {
					#address-cells = <0x01>;
					#size-cells = <0x00>;
					port@0 {
						reg = <0x00>;
						endpoint {
							remote-endpoint = <0x3d>;
							phandle = <0x3a>;
						};
					};
					port@1 {
						reg = <0x01>;
						endpoint {
							remote-endpoint = <0x3e>;
							phandle = <0x38>;
						};
					};
				};
			};
			dphy1 {
				compatible = "sprd,qogirn6pro-dsi1-phy";
				#address-cells = <0x01>;
				#size-cells = <0x00>;
				reg = <0x00 0x31400000 0x00 0x1000>;
				enable-syscon = <0x2d 0x1c 0x0c>;
				power-syscon = <0x04 0x9c 0x40>;
				syscon-names = "enable", "power";
				status = "okay";
				dev-id = <0x01>;
				sprd,ip = "sprd,megacores-sharkl5";
				sprd,soc = "qogirn6pro_s";
				sprd,mipi-drive-capability = <0x07>;
				phandle = <0x3c>;
				port@1 {
					reg = <0x01>;
					endpoint {
						remote-endpoint = <0x3f>;
						phandle = <0x3b>;
					};
				};
			};
		};
		aon {
			pwm@30000 {
				compatible = "sprd,qogirn6pro-pwm";
				reg = <0x30000 0x10000>;
				clock-names = "pwm0", "enable0", "pwm1", "enable1", "pwm2", "enable2", "pwm3", "enable3";
				clocks = <0x0a 0x02 0x11 0x3d 0x0a 0x03 0x11 0x3e 0x0a 0x04 0x11 0x3f 0x0a 0x05 0x11 0x40>;
				assigned-clocks = <0x0a 0x02 0x0a 0x03 0x0a 0x04 0x0a 0x05>;
				assigned-clock-parents = <0x09 0x64 0x09 0x09>;
				#pwm-cells = <0x02>;
				status = "okay";
				phandle = <0x17a>;
			};
		};
	};
	dpu-dvfs {
		compatible = "sprd,hwdvfs-dpu-qogirn6pro";
		sprd,hw-dfs-en = <0x04>;
		sprd,work-index-def = <0x06>;
		sprd,idle-index-def = <0x01>;
		sprd,freq-upd-delay-en = <0x00>;
		sprd,freq-upd-hdsk-en = <0x01>;
		operating-points = <0x3e800 0x9eb10 0x4b000 0x9eb10 0x5dc00 0xaae60 0x64000 0xaae60 0x7d000 0xb71b0 0x96000 0xb71b0>;
		phandle = <0x1f8>;
	};
	gsp-dvfs {
		compatible = "sprd,hwdvfs-gsp-qogirn6pro";
		sprd,hw-dfs-en = <0x00>;
		sprd,work-index-def = <0x03>;
		sprd,idle-index-def = <0x01>;
		sprd,freq-upd-delay-en = <0x00>;
		sprd,freq-upd-hdsk-en = <0x01>;
		operating-points = <0x3e800 0x927c0 0x4b000 0x9eb10 0x5dc00 0xaae60 0x7d000 0xb71b0>;
		phandle = <0x1f9>;
	};
	display-subsystem {
		compatible = "sprd,display-subsystem";
		ports = <0x130 0x131>;
		gsp = <0x132 0x133>;
	};
	__symbols__ {
		pwm_backlight = "/backlight";
		dummy_timing0 = "/lcds/lcd_dummy_mipi_hd/display-timings/timing0";
		lcd_dummy_mipi_hd = "/lcds/lcd_dummy_mipi_hd";
		lcd_dijing_ft8205p_longteng_fhd_timing0 = "/lcds/lcd_dijing_ft8205p_longteng_mipi_hdplus_focal/display-timings/timing0";
		lcd_dijing_ft8205p_longteng_mipi_hdplus_focal = "/lcds/lcd_dijing_ft8205p_longteng_mipi_hdplus_focal";
		lcd_dijing_hx83102j_huaxing_fhd_timing1 = "/lcds/lcd_dijing_hx83102j_huaxing_mipi_hdplus_himax/display-timings/timing1";
		lcd_dijing_hx83102j_huaxing_fhd_timing0 = "/lcds/lcd_dijing_hx83102j_huaxing_mipi_hdplus_himax/display-timings/timing0";
		lcd_dijing_hx83102j_huaxing_mipi_hdplus_himax = "/lcds/lcd_dijing_hx83102j_huaxing_mipi_hdplus_himax";
		lcd_lectron_hx83102j_huaxing_nopen_fhd_timing1 = "/lcds/lcd_lectron_hx83102j_huaxing_nopen_mipi_himax/display-timings/timing1";
		lcd_lectron_hx83102j_huaxing_nopen_fhd_timing0 = "/lcds/lcd_lectron_hx83102j_huaxing_nopen_mipi_himax/display-timings/timing0";
		lcd_lectron_hx83102j_huaxing_nopen_mipi_himax = "/lcds/lcd_lectron_hx83102j_huaxing_nopen_mipi_himax";
		lcd_lectron_hx83102j_huaxing_fhd_timing0 = "/lcds/lcd_lectron_hx83102j_huaxing_mipi_hdplus_himax/display-timings/timing0";
		lcd_lectron_hx83102j_huaxing_mipi_hdplus_himax = "/lcds/lcd_lectron_hx83102j_huaxing_mipi_hdplus_himax";
		lcd_huaying_hx83102j_huaying_fhd_timing1 = "/lcds/lcd_huaying_hx83102j_huaying_mipi_hdplus_himax/display-timings/timing1";
		lcd_huaying_hx83102j_huaying_fhd_timing0 = "/lcds/lcd_huaying_hx83102j_huaying_mipi_hdplus_himax/display-timings/timing0";
		lcd_huaying_hx83102j_huaying_mipi_hdplus_himax = "/lcds/lcd_huaying_hx83102j_huaying_mipi_hdplus_himax";
		lcd_lead_hx83102j_hsd_fhd_timing1 = "/lcds/lcd_lead_hx83102j_hsd_mipi_hdplus_himax/display-timings/timing1";
		lcd_lead_hx83102j_hsd_fhd_timing0 = "/lcds/lcd_lead_hx83102j_hsd_mipi_hdplus_himax/display-timings/timing0";
		lcd_lead_hx83102j_hsd_mipi_hdplus_himax = "/lcds/lcd_lead_hx83102j_hsd_mipi_hdplus_himax";
		lcd_lead_icnl9951r_hsd_fhd_timing1 = "/lcds/lcd_lead_icnl9951r_hsd_mipi_hdplus_chipone/display-timings/timing1";
		lcd_lead_icnl9951r_hsd_fhd_timing0 = "/lcds/lcd_lead_icnl9951r_hsd_mipi_hdplus_chipone/display-timings/timing0";
		lcd_lead_icnl9951r_hsd_mipi_hdplus_chipone = "/lcds/lcd_lead_icnl9951r_hsd_mipi_hdplus_chipone";
		lcd_guoxian_hx83102j_huaxing_nopen_fhd_timing1 = "/lcds/lcd_guoxian_hx83102j_huaxing_nopen_mipi_himax/display-timings/timing1";
		lcd_guoxian_hx83102j_huaxing_nopen_fhd_timing0 = "/lcds/lcd_guoxian_hx83102j_huaxing_nopen_mipi_himax/display-timings/timing0";
		lcd_guoxian_hx83102j_huaxing_nopen_mipi_himax = "/lcds/lcd_guoxian_hx83102j_huaxing_nopen_mipi_himax";
		dpu = "/soc/dpuvsp/dpu@31000000";
		dpu_port = "/soc/dpuvsp/dpu@31000000/port";
		dpu_out = "/soc/dpuvsp/dpu@31000000/port/endpoint";
		iommu_dispc = "/soc/dpuvsp/iommu@31001800";
		gsp0_core0 = "/soc/dpuvsp/gsp@31100000";
		iommu_gsp = "/soc/dpuvsp/iommu@31100000";
		gsp1_core0 = "/soc/dpuvsp/gsp@31200000";
		iommu_gsp1 = "/soc/dpuvsp/iommu@31200000";
		dsi = "/soc/dpuvsp/dsi@31300000";
		dsi_out = "/soc/dpuvsp/dsi@31300000/ports/port@0/endpoint";
		dsi_in = "/soc/dpuvsp/dsi@31300000/ports/port@1/endpoint";
		panel = "/soc/dpuvsp/dsi@31300000/panel";
		panel_in = "/soc/dpuvsp/dsi@31300000/panel/port@1/endpoint";
		dsi1 = "/soc/dpuvsp/dsi1@31400000";
		dsi1_out = "/soc/dpuvsp/dsi1@31400000/ports/port@0/endpoint";
		dphy = "/soc/dpuvsp/dphy";
		dphy_out = "/soc/dpuvsp/dphy/ports/port@0/endpoint";
		dphy_in = "/soc/dpuvsp/dphy/ports/port@1/endpoint";
		dphy1 = "/soc/dpuvsp/dphy1";
		dphy1_in = "/soc/dpuvsp/dphy1/port@1/endpoint";
		pwms = "/soc/aon/pwm@30000";
		dpu_dvfs = "/dpu-dvfs";
		gsp_dvfs = "/gsp-dvfs";
	};
};
